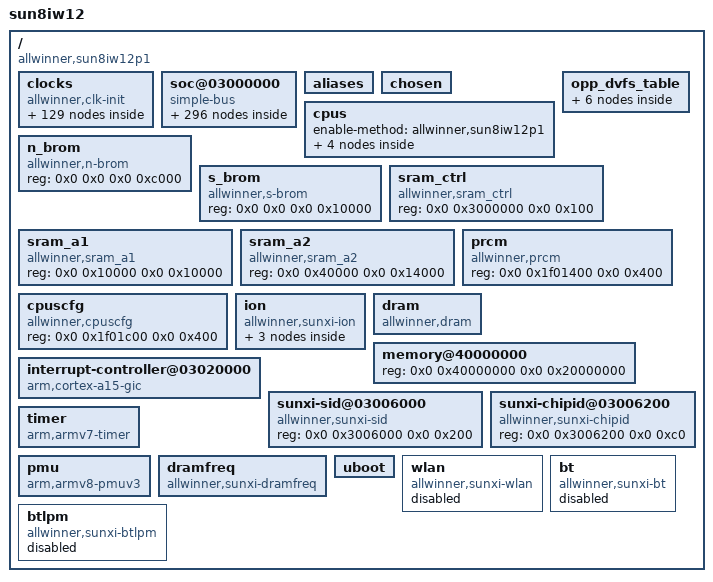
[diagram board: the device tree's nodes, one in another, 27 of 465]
/dts-v1/;

/memreserve/	0x0000000040020000 0x0000000000000800;
/memreserve/	0x0000000048100000 0x0000000000004000;
/memreserve/	0x0000000048104000 0x0000000000001000;
/memreserve/	0x0000000048105000 0x0000000000001000;
/ {
	model = "sun8iw12";
	compatible = "allwinner,sun8iw12p1";
	interrupt-parent = <0x1>;
	#address-cells = <0x2>;
	#size-cells = <0x2>;

	clocks {
		compatible = "allwinner,clk-init";
		device_type = "clocks";
		#address-cells = <0x2>;
		#size-cells = <0x2>;
		ranges;
		reg = <0x0 0x3001000 0x0 0x1000 0x0 0x7010000 0x0 0x400 0x0 0x7000060 0x0 0x4>;

		losc {
			#clock-cells = <0x0>;
			compatible = "allwinner,fixed-clock";
			clock-frequency = <0x8000>;
			clock-output-names = "losc";
			linux,phandle = <0x12>;
			phandle = <0x12>;
		};

		iosc {
			#clock-cells = <0x0>;
			compatible = "allwinner,fixed-clock";
			clock-frequency = <0xf42400>;
			clock-output-names = "iosc";
			linux,phandle = <0x13>;
			phandle = <0x13>;
		};

		hosc {
			#clock-cells = <0x0>;
			compatible = "allwinner,fixed-clock";
			clock-frequency = <0x16e3600>;
			clock-output-names = "hosc";
			linux,phandle = <0x6>;
			phandle = <0x6>;
		};

		osc48m {
			#clock-cells = <0x0>;
			compatible = "allwinner,fixed-clock";
			clock-frequency = <0x2dc6c00>;
			clock-output-names = "osc48m";
			linux,phandle = <0x7>;
			phandle = <0x7>;
		};

		pll_cpu {
			#clock-cells = <0x0>;
			compatible = "allwinner,pll-clock";
			lock-mode = "new";
			clock-output-names = "pll_cpu";
			linux,phandle = <0xc4>;
			phandle = <0xc4>;
		};

		pll_ddr0 {
			#clock-cells = <0x0>;
			compatible = "allwinner,pll-clock";
			lock-mode = "new";
			clock-output-names = "pll_ddr0";
			linux,phandle = <0xc6>;
			phandle = <0xc6>;
		};

		pll_ddr1 {
			#clock-cells = <0x0>;
			compatible = "allwinner,pll-clock";
			lock-mode = "new";
			clock-output-names = "pll_ddr1";
			linux,phandle = <0xc7>;
			phandle = <0xc7>;
		};

		pll_periph0 {
			#clock-cells = <0x0>;
			compatible = "allwinner,pll-clock";
			assigned-clock-rates = <0x23c34600>;
			lock-mode = "new";
			clock-output-names = "pll_periph0";
			linux,phandle = <0x2>;
			phandle = <0x2>;
		};

		pll_periph1 {
			#clock-cells = <0x0>;
			compatible = "allwinner,pll-clock";
			assigned-clock-rates = <0x23c34600>;
			lock-mode = "new";
			clock-output-names = "pll_periph1";
			linux,phandle = <0x3>;
			phandle = <0x3>;
		};

		pll_video0 {
			#clock-cells = <0x0>;
			compatible = "allwinner,pll-clock";
			lock-mode = "new";
			clock-output-names = "pll_video0";
			linux,phandle = <0x5>;
			phandle = <0x5>;
		};

		pll_ve {
			#clock-cells = <0x0>;
			compatible = "allwinner,pll-clock";
			device_type = "clk_pll_ve";
			lock-mode = "new";
			clock-output-names = "pll_ve";
			linux,phandle = <0x23>;
			phandle = <0x23>;
		};

		pll_de {
			#clock-cells = <0x0>;
			compatible = "allwinner,pll-clock";
			lock-mode = "new";
			clock-output-names = "pll_de";
			linux,phandle = <0x9>;
			phandle = <0x9>;
		};

		pll_isp {
			#clock-cells = <0x0>;
			compatible = "allwinner,pll-clock";
			lock-mode = "new";
			clock-output-names = "pll_isp";
			linux,phandle = <0x95>;
			phandle = <0x95>;
		};

		pll_audio {
			#clock-cells = <0x0>;
			compatible = "allwinner,pll-clock";
			lock-mode = "new";
			clock-output-names = "pll_audio";
			linux,phandle = <0x4>;
			phandle = <0x4>;
		};

		pll_eve {
			#clock-cells = <0x0>;
			compatible = "allwinner,pll-clock";
			device_type = "clk_pll_eve";
			lock-mode = "new";
			clock-output-names = "pll_eve";
			linux,phandle = <0x1d>;
			phandle = <0x1d>;
		};

		pll_cve {
			#clock-cells = <0x0>;
			compatible = "allwinner,pll-clock";
			lock-mode = "new";
			clock-output-names = "pll_cve";
			linux,phandle = <0x1f>;
			phandle = <0x1f>;
		};

		pll_ise {
			#clock-cells = <0x0>;
			compatible = "allwinner,pll-clock";
			lock-mode = "new";
			clock-output-names = "pll_ise";
			linux,phandle = <0x21>;
			phandle = <0x21>;
		};

		pll_periph0x2 {
			#clock-cells = <0x0>;
			compatible = "allwinner,fixed-factor-clock";
			clocks = <0x2>;
			clock-mult = <0x2>;
			clock-div = <0x1>;
			clock-output-names = "pll_periph0x2";
			linux,phandle = <0x70>;
			phandle = <0x70>;
		};

		periph32k {
			#clock-cells = <0x0>;
			compatible = "allwinner,fixed-factor-clock";
			clocks = <0x2>;
			clock-mult = <0x2>;
			clock-div = <0x8f0d>;
			clock-output-names = "periph32k";
			linux,phandle = <0xb>;
			phandle = <0xb>;
		};

		pll_periph1x2 {
			#clock-cells = <0x0>;
			compatible = "allwinner,fixed-factor-clock";
			clocks = <0x3>;
			clock-mult = <0x2>;
			clock-div = <0x1>;
			clock-output-names = "pll_periph1x2";
			linux,phandle = <0xb0>;
			phandle = <0xb0>;
		};

		pll_periph0d24 {
			#clock-cells = <0x0>;
			compatible = "allwinner,fixed-factor-clock";
			clocks = <0x2>;
			clock-mult = <0x1>;
			clock-div = <0x18>;
			clock-output-names = "pll_periph0d24";
		};

		pll_audiox4 {
			#clock-cells = <0x0>;
			compatible = "allwinner,fixed-factor-clock";
			clocks = <0x4>;
			clock-mult = <0x4>;
			clock-div = <0x1>;
			clock-output-names = "pll_audiox4";
		};

		pll_audiox2 {
			#clock-cells = <0x0>;
			compatible = "allwinner,fixed-factor-clock";
			clocks = <0x4>;
			clock-mult = <0x2>;
			clock-div = <0x1>;
			clock-output-names = "pll_audiox2";
		};

		pll_video0x4 {
			#clock-cells = <0x0>;
			compatible = "allwinner,fixed-factor-clock";
			clocks = <0x5>;
			clock-mult = <0x4>;
			clock-div = <0x1>;
			clock-output-names = "pll_video0x4";
		};

		hoscd2 {
			#clock-cells = <0x0>;
			compatible = "allwinner,fixed-factor-clock";
			clocks = <0x6>;
			clock-mult = <0x1>;
			clock-div = <0x2>;
			clock-output-names = "hoscd2";
		};

		osc48md4 {
			#clock-cells = <0x0>;
			compatible = "allwinner,fixed-factor-clock";
			clocks = <0x7>;
			clock-mult = <0x1>;
			clock-div = <0x4>;
			clock-output-names = "osc48md4";
			linux,phandle = <0x45>;
			phandle = <0x45>;
		};

		cpu {
			#clock-cells = <0x0>;
			compatible = "allwinner,periph-clock";
			clock-output-names = "cpu";
		};

		axi {
			#clock-cells = <0x0>;
			compatible = "allwinner,periph-clock";
			clock-output-names = "axi";
		};

		cpuapb {
			#clock-cells = <0x0>;
			compatible = "allwinner,periph-clock";
			clock-output-names = "cpuapb";
		};

		psi {
			#clock-cells = <0x0>;
			compatible = "allwinner,periph-clock";
			clock-output-names = "psi";
		};

		ahb1 {
			#clock-cells = <0x0>;
			compatible = "allwinner,periph-clock";
			clock-output-names = "ahb1";
		};

		ahb2 {
			#clock-cells = <0x0>;
			compatible = "allwinner,periph-clock";
			clock-output-names = "ahb2";
		};

		ahb3 {
			#clock-cells = <0x0>;
			compatible = "allwinner,periph-clock";
			clock-output-names = "ahb3";
		};

		apb1 {
			#clock-cells = <0x0>;
			compatible = "allwinner,periph-clock";
			clock-output-names = "apb1";
		};

		apb2 {
			#clock-cells = <0x0>;
			compatible = "allwinner,periph-clock";
			clock-output-names = "apb2";
		};

		mbus {
			#clock-cells = <0x0>;
			compatible = "allwinner,periph-clock";
			clock-output-names = "mbus";
		};

		de {
			#clock-cells = <0x0>;
			compatible = "allwinner,periph-clock";
			assigned-clocks = <0x8>;
			assigned-clock-parents = <0x9>;
			assigned-clock-rates = <0x19bfcc00>;
			clock-output-names = "de";
			linux,phandle = <0x8>;
			phandle = <0x8>;
		};

		di {
			#clock-cells = <0x0>;
			compatible = "allwinner,periph-clock";
			clock-output-names = "di";
			linux,phandle = <0xaf>;
			phandle = <0xaf>;
		};

		g2d {
			#clock-cells = <0x0>;
			compatible = "allwinner,periph-clock";
			clock-output-names = "g2d";
			linux,phandle = <0x87>;
			phandle = <0x87>;
		};

		ve {
			#clock-cells = <0x0>;
			compatible = "allwinner,periph-clock";
			clock-output-names = "ve";
			linux,phandle = <0x24>;
			phandle = <0x24>;
		};

		eve {
			#clock-cells = <0x0>;
			compatible = "allwinner,periph-clock";
			clock-output-names = "eve";
			linux,phandle = <0x1e>;
			phandle = <0x1e>;
		};

		cve {
			#clock-cells = <0x0>;
			compatible = "allwinner,periph-clock";
			clock-output-names = "cve";
			linux,phandle = <0x20>;
			phandle = <0x20>;
		};

		ce {
			#clock-cells = <0x0>;
			compatible = "allwinner,periph-clock";
			clock-output-names = "ce";
			linux,phandle = <0xae>;
			phandle = <0xae>;
		};

		ise {
			#clock-cells = <0x0>;
			compatible = "allwinner,periph-clock";
			clock-output-names = "ise";
			linux,phandle = <0x22>;
			phandle = <0x22>;
		};

		isp {
			#clock-cells = <0x0>;
			compatible = "allwinner,periph-clock";
			clock-output-names = "isp";
			linux,phandle = <0x9a>;
			phandle = <0x9a>;
		};

		dma {
			#clock-cells = <0x0>;
			compatible = "allwinner,periph-clock";
			clock-output-names = "dma";
			linux,phandle = <0x11>;
			phandle = <0x11>;
		};

		msgbox {
			#clock-cells = <0x0>;
			compatible = "allwinner,periph-clock";
			clock-output-names = "msgbox";
			linux,phandle = <0x14>;
			phandle = <0x14>;
		};

		hwspinlock_rst {
			#clock-cells = <0x0>;
			compatible = "allwinner,periph-clock";
			clock-output-names = "hwspinlock_rst";
			linux,phandle = <0x15>;
			phandle = <0x15>;
		};

		hwspinlock_bus {
			#clock-cells = <0x0>;
			compatible = "allwinner,periph-clock";
			clock-output-names = "hwspinlock_bus";
			linux,phandle = <0x16>;
			phandle = <0x16>;
		};

		hstimer {
			#clock-cells = <0x0>;
			compatible = "allwinner,periph-clock";
			clock-output-names = "hstimer";
		};

		avs {
			#clock-cells = <0x0>;
			compatible = "allwinner,periph-clock";
			clock-output-names = "avs";
		};

		dbgsys {
			#clock-cells = <0x0>;
			compatible = "allwinner,periph-clock";
			clock-output-names = "dbgsys";
		};

		pwm {
			#clock-cells = <0x0>;
			compatible = "allwinner,periph-clock";
			clock-output-names = "pwm";
			linux,phandle = <0x88>;
			phandle = <0x88>;
		};

		sdram {
			#clock-cells = <0x0>;
			compatible = "allwinner,periph-clock";
			clock-output-names = "sdram";
		};

		nand0 {
			#clock-cells = <0x0>;
			compatible = "allwinner,periph-clock";
			clock-output-names = "nand0";
			linux,phandle = <0xb1>;
			phandle = <0xb1>;
		};

		nand1 {
			#clock-cells = <0x0>;
			compatible = "allwinner,periph-clock";
			clock-output-names = "nand1";
			linux,phandle = <0xb2>;
			phandle = <0xb2>;
		};

		sdmmc0_mod {
			#clock-cells = <0x0>;
			compatible = "allwinner,periph-clock";
			clock-output-names = "sdmmc0_mod";
			linux,phandle = <0x76>;
			phandle = <0x76>;
		};

		sdmmc0_bus {
			#clock-cells = <0x0>;
			compatible = "allwinner,periph-clock";
			clock-output-names = "sdmmc0_bus";
			linux,phandle = <0x77>;
			phandle = <0x77>;
		};

		sdmmc0_rst {
			#clock-cells = <0x0>;
			compatible = "allwinner,periph-clock";
			clock-output-names = "sdmmc0_rst";
			linux,phandle = <0x78>;
			phandle = <0x78>;
		};

		sdmmc1_mod {
			#clock-cells = <0x0>;
			compatible = "allwinner,periph-clock";
			clock-output-names = "sdmmc1_mod";
			linux,phandle = <0x7b>;
			phandle = <0x7b>;
		};

		sdmmc1_bus {
			#clock-cells = <0x0>;
			compatible = "allwinner,periph-clock";
			clock-output-names = "sdmmc1_bus";
			linux,phandle = <0x7c>;
			phandle = <0x7c>;
		};

		sdmmc1_rst {
			#clock-cells = <0x0>;
			compatible = "allwinner,periph-clock";
			clock-output-names = "sdmmc1_rst";
			linux,phandle = <0x7d>;
			phandle = <0x7d>;
		};

		sdmmc2_mod {
			#clock-cells = <0x0>;
			compatible = "allwinner,periph-clock";
			clock-output-names = "sdmmc2_mod";
			linux,phandle = <0x71>;
			phandle = <0x71>;
		};

		sdmmc2_bus {
			#clock-cells = <0x0>;
			compatible = "allwinner,periph-clock";
			clock-output-names = "sdmmc2_bus";
			linux,phandle = <0x72>;
			phandle = <0x72>;
		};

		sdmmc2_rst {
			#clock-cells = <0x0>;
			compatible = "allwinner,periph-clock";
			clock-output-names = "sdmmc2_rst";
			linux,phandle = <0x73>;
			phandle = <0x73>;
		};

		uart0 {
			#clock-cells = <0x0>;
			compatible = "allwinner,periph-clock";
			clock-output-names = "uart0";
			linux,phandle = <0x25>;
			phandle = <0x25>;
		};

		uart1 {
			#clock-cells = <0x0>;
			compatible = "allwinner,periph-clock";
			clock-output-names = "uart1";
			linux,phandle = <0x28>;
			phandle = <0x28>;
		};

		uart2 {
			#clock-cells = <0x0>;
			compatible = "allwinner,periph-clock";
			clock-output-names = "uart2";
			linux,phandle = <0x2b>;
			phandle = <0x2b>;
		};

		uart3 {
			#clock-cells = <0x0>;
			compatible = "allwinner,periph-clock";
			clock-output-names = "uart3";
			linux,phandle = <0x2e>;
			phandle = <0x2e>;
		};

		uart4 {
			#clock-cells = <0x0>;
			compatible = "allwinner,periph-clock";
			clock-output-names = "uart4";
			linux,phandle = <0x31>;
			phandle = <0x31>;
		};

		twi0 {
			#clock-cells = <0x0>;
			compatible = "allwinner,periph-clock";
			clock-output-names = "twi0";
			linux,phandle = <0x34>;
			phandle = <0x34>;
		};

		twi1 {
			#clock-cells = <0x0>;
			compatible = "allwinner,periph-clock";
			clock-output-names = "twi1";
			linux,phandle = <0x37>;
			phandle = <0x37>;
		};

		twi2 {
			#clock-cells = <0x0>;
			compatible = "allwinner,periph-clock";
			clock-output-names = "twi2";
			linux,phandle = <0x3a>;
			phandle = <0x3a>;
		};

		twi3 {
			#clock-cells = <0x0>;
			compatible = "allwinner,periph-clock";
			clock-output-names = "twi3";
			linux,phandle = <0x3d>;
			phandle = <0x3d>;
		};

		spi0 {
			#clock-cells = <0x0>;
			compatible = "allwinner,periph-clock";
			clock-output-names = "spi0";
			linux,phandle = <0x60>;
			phandle = <0x60>;
		};

		spi1 {
			#clock-cells = <0x0>;
			compatible = "allwinner,periph-clock";
			clock-output-names = "spi1";
			linux,phandle = <0x64>;
			phandle = <0x64>;
		};

		spi2 {
			#clock-cells = <0x0>;
			compatible = "allwinner,periph-clock";
			clock-output-names = "spi2";
			linux,phandle = <0x68>;
			phandle = <0x68>;
		};

		spi3 {
			#clock-cells = <0x0>;
			compatible = "allwinner,periph-clock";
			clock-output-names = "spi3";
			linux,phandle = <0x6c>;
			phandle = <0x6c>;
		};

		ephy_25m {
			#clock-cells = <0x0>;
			compatible = "allwinner,periph-clock";
			clock-output-names = "ephy_25m";
			linux,phandle = <0xc1>;
			phandle = <0xc1>;
		};

		gmac {
			#clock-cells = <0x0>;
			compatible = "allwinner,periph-clock";
			clock-output-names = "gmac";
			linux,phandle = <0xc0>;
			phandle = <0xc0>;
		};

		gpadc {
			#clock-cells = <0x0>;
			compatible = "allwinner,periph-clock";
			clock-output-names = "gpadc";
			linux,phandle = <0xbf>;
			phandle = <0xbf>;
		};

		ths {
			#clock-cells = <0x0>;
			compatible = "allwinner,periph-clock";
			clock-output-names = "ths";
			linux,phandle = <0xb6>;
			phandle = <0xb6>;
		};

		i2s0 {
			#clock-cells = <0x0>;
			compatible = "allwinner,periph-clock";
			clock-output-names = "i2s0";
			linux,phandle = <0x50>;
			phandle = <0x50>;
		};

		i2s1 {
			#clock-cells = <0x0>;
			compatible = "allwinner,periph-clock";
			clock-output-names = "i2s1";
			linux,phandle = <0x53>;
			phandle = <0x53>;
		};

		i2s2 {
			#clock-cells = <0x0>;
			compatible = "allwinner,periph-clock";
			clock-output-names = "i2s2";
			linux,phandle = <0x54>;
			phandle = <0x54>;
		};

		dmic {
			#clock-cells = <0x0>;
			compatible = "allwinner,periph-clock";
			clock-output-names = "dmic";
			linux,phandle = <0x57>;
			phandle = <0x57>;
		};

		codec_1x {
			#clock-cells = <0x0>;
			compatible = "allwinner,periph-clock";
			clock-output-names = "codec_1x";
			linux,phandle = <0x4a>;
			phandle = <0x4a>;
		};

		codec_4x {
			#clock-cells = <0x0>;
			compatible = "allwinner,periph-clock";
			clock-output-names = "codec_4x";
		};

		usbphy0 {
			#clock-cells = <0x0>;
			compatible = "allwinner,periph-clock";
			clock-output-names = "usbphy0";
			linux,phandle = <0x40>;
			phandle = <0x40>;
		};

		usbphy1 {
			#clock-cells = <0x0>;
			compatible = "allwinner,periph-clock";
			clock-output-names = "usbphy1";
			linux,phandle = <0x46>;
			phandle = <0x46>;
		};

		usbohci0 {
			#clock-cells = <0x0>;
			compatible = "allwinner,periph-clock";
			clock-output-names = "usbohci0";
			linux,phandle = <0x43>;
			phandle = <0x43>;
		};

		usbohci0_12m {
			#clock-cells = <0x0>;
			compatible = "allwinner,periph-clock";
			clock-output-names = "usbohci0_12m";
			linux,phandle = <0x44>;
			phandle = <0x44>;
		};

		usbohci1 {
			#clock-cells = <0x0>;
			compatible = "allwinner,periph-clock";
			clock-output-names = "usbohci1";
			linux,phandle = <0x48>;
			phandle = <0x48>;
		};

		usbohci1_12m {
			#clock-cells = <0x0>;
			compatible = "allwinner,periph-clock";
			clock-output-names = "usbohci1_12m";
			linux,phandle = <0x49>;
			phandle = <0x49>;
		};

		usbehci0 {
			#clock-cells = <0x0>;
			compatible = "allwinner,periph-clock";
			clock-output-names = "usbehci0";
			linux,phandle = <0x42>;
			phandle = <0x42>;
		};

		usbehci1 {
			#clock-cells = <0x0>;
			compatible = "allwinner,periph-clock";
			clock-output-names = "usbehci1";
			linux,phandle = <0x47>;
			phandle = <0x47>;
		};

		usbotg {
			#clock-cells = <0x0>;
			compatible = "allwinner,periph-clock";
			clock-output-names = "usbotg";
			linux,phandle = <0x41>;
			phandle = <0x41>;
		};

		hdmi {
			#clock-cells = <0x0>;
			compatible = "allwinner,periph-clock";
			clock-output-names = "hdmi";
			linux,phandle = <0x83>;
			phandle = <0x83>;
		};

		hdmi_slow {
			#clock-cells = <0x0>;
			compatible = "allwinner,periph-clock";
			clock-output-names = "hdmi_slow";
			linux,phandle = <0x84>;
			phandle = <0x84>;
		};

		hdmi_cec {
			#clock-cells = <0x0>;
			compatible = "allwinner,periph-clock";
			assigned-clocks = <0xa>;
			assigned-clock-parents = <0xb>;
			clock-output-names = "hdmi_cec";
			linux,phandle = <0xa>;
			phandle = <0xa>;
		};

		mipi_dphy0 {
			#clock-cells = <0x0>;
			compatible = "allwinner,periph-clock";
			clock-output-names = "mipi_dphy0";
			linux,phandle = <0x82>;
			phandle = <0x82>;
		};

		mipi_host0 {
			#clock-cells = <0x0>;
			compatible = "allwinner,periph-clock";
			assigned-clocks = <0xc>;
			assigned-clock-parents = <0x6>;
			clock-output-names = "mipi_host0";
			linux,phandle = <0xc>;
			phandle = <0xc>;
		};

		display_top {
			#clock-cells = <0x0>;
			compatible = "allwinner,periph-clock";
			clock-output-names = "display_top";
			linux,phandle = <0x80>;
			phandle = <0x80>;
		};

		tcon_lcd {
			#clock-cells = <0x0>;
			compatible = "allwinner,periph-clock";
			clock-output-names = "tcon_lcd";
			linux,phandle = <0xe>;
			phandle = <0xe>;
		};

		tcon_tv {
			#clock-cells = <0x0>;
			compatible = "allwinner,periph-clock";
			clock-output-names = "tcon_tv";
			linux,phandle = <0x81>;
			phandle = <0x81>;
		};

		lvds {
			#clock-cells = <0x0>;
			compatible = "allwinner,periph-clock";
			assigned-clocks = <0xd>;
			assigned-clock-parents = <0xe>;
			clock-output-names = "lvds";
			linux,phandle = <0xd>;
			phandle = <0xd>;
		};

		tve {
			#clock-cells = <0x0>;
			compatible = "allwinner,periph-clock";
			clock-output-names = "tve";
			linux,phandle = <0x86>;
			phandle = <0x86>;
		};

		tve_top {
			#clock-cells = <0x0>;
			compatible = "allwinner,periph-clock";
			clock-output-names = "tve_top";
			linux,phandle = <0x85>;
			phandle = <0x85>;
		};

		csi_misc0 {
			#clock-cells = <0x0>;
			compatible = "allwinner,periph-clock";
			clock-output-names = "csi_misc0";
			linux,phandle = <0xa3>;
			phandle = <0xa3>;
		};

		csi_misc1 {
			#clock-cells = <0x0>;
			compatible = "allwinner,periph-clock";
			clock-output-names = "csi_misc1";
			linux,phandle = <0xa4>;
			phandle = <0xa4>;
		};

		csi_misc2 {
			#clock-cells = <0x0>;
			compatible = "allwinner,periph-clock";
			clock-output-names = "csi_misc2";
			linux,phandle = <0xa5>;
			phandle = <0xa5>;
		};

		csi_misc3 {
			#clock-cells = <0x0>;
			compatible = "allwinner,periph-clock";
			clock-output-names = "csi_misc3";
			linux,phandle = <0xa6>;
			phandle = <0xa6>;
		};

		csi_top {
			#clock-cells = <0x0>;
			compatible = "allwinner,periph-clock";
			clock-output-names = "csi_top";
			linux,phandle = <0x94>;
			phandle = <0x94>;
		};

		csi_master0 {
			#clock-cells = <0x0>;
			compatible = "allwinner,periph-clock";
			clock-output-names = "csi_master0";
			linux,phandle = <0x96>;
			phandle = <0x96>;
		};

		csi_master1 {
			#clock-cells = <0x0>;
			compatible = "allwinner,periph-clock";
			clock-output-names = "csi_master1";
			linux,phandle = <0x97>;
			phandle = <0x97>;
		};

		csi_master2 {
			#clock-cells = <0x0>;
			compatible = "allwinner,periph-clock";
			clock-output-names = "csi_master2";
			linux,phandle = <0x98>;
			phandle = <0x98>;
		};

		csi_master3 {
			#clock-cells = <0x0>;
			compatible = "allwinner,periph-clock";
			clock-output-names = "csi_master3";
			linux,phandle = <0x99>;
			phandle = <0x99>;
		};

		vdpo {
			#clock-cells = <0x0>;
			compatible = "allwinner,periph-clock";
			clock-output-names = "vdpo";
		};

		pio {
			#clock-cells = <0x0>;
			compatible = "allwinner,periph-clock";
			clock-output-names = "pio";
			linux,phandle = <0x10>;
			phandle = <0x10>;
		};

		cpurcir {
			#clock-cells = <0x0>;
			compatible = "allwinner,periph-cpus-clock";
			clock-output-names = "cpurcir";
			linux,phandle = <0x18>;
			phandle = <0x18>;
		};

		losc_out {
			#clock-cells = <0x0>;
			compatible = "allwinner,periph-cpus-clock";
			clock-output-names = "losc_out";
			linux,phandle = <0xc8>;
			phandle = <0xc8>;
		};

		cpurcpus_pll {
			#clock-cells = <0x0>;
			compatible = "allwinner,periph-cpus-clock";
			clock-output-names = "cpurcpus_pll";
		};

		cpurcpus {
			#clock-cells = <0x0>;
			compatible = "allwinner,periph-cpus-clock";
			clock-output-names = "cpurcpus";
		};

		cpurahbs {
			#clock-cells = <0x0>;
			compatible = "allwinner,periph-cpus-clock";
			clock-output-names = "cpurahbs";
		};

		cpurapbs1 {
			#clock-cells = <0x0>;
			compatible = "allwinner,periph-cpus-clock";
			clock-output-names = "cpurapbs1";
		};

		cpurapbs2_pll {
			#clock-cells = <0x0>;
			compatible = "allwinner,periph-cpus-clock";
			clock-output-names = "cpurapbs2_pll";
		};

		cpurapbs2 {
			#clock-cells = <0x0>;
			compatible = "allwinner,periph-cpus-clock";
			clock-output-names = "cpurapbs2";
		};

		cpurpio {
			#clock-cells = <0x0>;
			compatible = "allwinner,periph-cpus-clock";
			clock-output-names = "cpurpio";
			linux,phandle = <0xf>;
			phandle = <0xf>;
		};

		spwm {
			#clock-cells = <0x0>;
			compatible = "allwinner,periph-cpus-clock";
			clock-output-names = "spwm";
			linux,phandle = <0x92>;
			phandle = <0x92>;
		};
	};

	soc@03000000 {
		compatible = "simple-bus";
		#address-cells = <0x2>;
		#size-cells = <0x2>;
		ranges;
		device_type = "soc";

		pinctrl@07022000 {
			compatible = "allwinner,sun8iw12p1-r-pinctrl";
			reg = <0x0 0x7022000 0x0 0x400>;
			interrupts = <0x0 0x6e 0x4>;
			clocks = <0xf>;
			device_type = "r_pio";
			gpio-controller;
			interrupt-controller;
			#interrupt-cells = <0x2>;
			#size-cells = <0x0>;
			#gpio-cells = <0x6>;
			linux,phandle = <0xc9>;
			phandle = <0xc9>;

			s_rsb0@0 {
				allwinner,pins = "PL0", "PL1";
				allwinner,function = "s_rsb0";
				allwinner,muxsel = <0x2>;
				allwinner,drive = <0x2>;
				allwinner,pull = <0x1>;
				linux,phandle = <0x1a>;
				phandle = <0x1a>;
			};

			s_twi0@0 {
				allwinner,pins = "PL0", "PL1";
				allwinner,function = "s_twi0";
				allwinner,muxsel = <0x3>;
				allwinner,drive = <0x2>;
				allwinner,pull = <0x1>;
				linux,phandle = <0x1b>;
				phandle = <0x1b>;
			};

			s_cir0@0 {
				allwinner,pins = "PL13";
				allwinner,function = "s_cir0";
				allwinner,muxsel = <0x2>;
				allwinner,drive = <0x2>;
				allwinner,pull = <0x1>;
				linux,phandle = <0x17>;
				phandle = <0x17>;
			};

			spwm0@0 {
				linux,phandle = <0xee>;
				phandle = <0xee>;
				allwinner,pins = "PL10";
				allwinner,function = "spwm0";
				allwinner,pname = "pwm_positive";
				allwinner,muxsel = <0x2>;
				allwinner,pull = <0x0>;
				allwinner,drive = <0xffffffff>;
				allwinner,data = <0xffffffff>;
			};

			spwm0@1 {
				linux,phandle = <0xef>;
				phandle = <0xef>;
				allwinner,pins = "PL10";
				allwinner,function = "spwm0";
				allwinner,pname = "pwm_positive";
				allwinner,muxsel = <0x7>;
				allwinner,pull = <0x0>;
				allwinner,drive = <0xffffffff>;
				allwinner,data = <0xffffffff>;
			};

			s_uart0@0 {
				linux,phandle = <0xf9>;
				phandle = <0xf9>;
				allwinner,pins = "PL2", "PL3";
				allwinner,function = "s_uart0";
				allwinner,pname = "s_uart_tx", "s_uart_rx";
				allwinner,muxsel = <0x2>;
				allwinner,pull = <0xffffffff>;
				allwinner,drive = <0xffffffff>;
				allwinner,data = <0xffffffff>;
			};

			s_rsb0@1 {
				linux,phandle = <0xfa>;
				phandle = <0xfa>;
				allwinner,pins = "PL0", "PL1";
				allwinner,function = "s_rsb0";
				allwinner,pname = "s_rsb_sck", "s_rsb_sda";
				allwinner,muxsel = <0x2>;
				allwinner,pull = <0x1>;
				allwinner,drive = <0x2>;
				allwinner,data = <0xffffffff>;
			};

			s_jtag0@0 {
				linux,phandle = <0xfb>;
				phandle = <0xfb>;
				allwinner,pins = "PL4", "PL5", "PL6", "PL7";
				allwinner,function = "s_jtag0";
				allwinner,pname = "s_jtag_tms", "s_jtag_tck", "s_jtag_tdo", "s_jtag_tdi";
				allwinner,muxsel = <0x2>;
				allwinner,pull = <0x1>;
				allwinner,drive = <0x2>;
				allwinner,data = <0xffffffff>;
			};
		};

		pinctrl@0300b000 {
			compatible = "allwinner,sun8iw12p1-pinctrl";
			reg = <0x0 0x300b000 0x0 0x400>;
			interrupts = <0x0 0x45 0x4 0x0 0x46 0x4 0x0 0x47 0x4 0x0 0x48 0x4 0x0 0x49 0x4>;
			device_type = "pio";
			clocks = <0x10>;
			gpio-controller;
			interrupt-controller;
			#interrupt-cells = <0x2>;
			#size-cells = <0x0>;
			#gpio-cells = <0x6>;
			linux,phandle = <0x4f>;
			phandle = <0x4f>;

			uart0@1 {
				allwinner,pins = "PB9", "PB10";
				allwinner,function = "io_disabled";
				allwinner,muxsel = <0x7>;
				allwinner,drive = <0x1>;
				allwinner,pull = <0x0>;
				linux,phandle = <0x27>;
				phandle = <0x27>;
			};

			uart3@0 {
				allwinner,pins = "PG10", "PG11", "PG12", "PG13";
				allwinner,pname = "uart3_tx", "uart3_rx", "uart3_rts", "uart3_cts";
				allwinner,function = "uart3";
				allwinner,muxsel = <0x4>;
				allwinner,drive = <0x1>;
				allwinner,pull = <0x1>;
				linux,phandle = <0x2f>;
				phandle = <0x2f>;
			};

			uart3@1 {
				allwinner,pins = "PG10", "PG11", "PG12", "PG13";
				allwinner,function = "io_disabled";
				allwinner,muxsel = <0x7>;
				allwinner,drive = <0x1>;
				allwinner,pull = <0x0>;
				linux,phandle = <0x30>;
				phandle = <0x30>;
			};

			twi0@1 {
				allwinner,pins = "PH0", "PH1";
				allwinner,function = "io_disabled";
				allwinner,muxsel = <0x7>;
				allwinner,drive = <0x1>;
				allwinner,pull = <0x0>;
				linux,phandle = <0x36>;
				phandle = <0x36>;
			};

			twi1@1 {
				allwinner,pins = "PH2", "PH3";
				allwinner,function = "io_disabled";
				allwinner,muxsel = <0x7>;
				allwinner,drive = <0x1>;
				allwinner,pull = <0x0>;
				linux,phandle = <0x39>;
				phandle = <0x39>;
			};

			twi2@1 {
				allwinner,pins = "PE16", "PE17";
				allwinner,function = "io_disabled";
				allwinner,muxsel = <0x7>;
				allwinner,drive = <0x1>;
				allwinner,pull = <0x0>;
				linux,phandle = <0x3c>;
				phandle = <0x3c>;
			};

			twi3@1 {
				allwinner,pins = "PI8", "PI9";
				allwinner,function = "io_disabled";
				allwinner,muxsel = <0x7>;
				allwinner,drive = <0x1>;
				allwinner,pull = <0x0>;
				linux,phandle = <0x3f>;
				phandle = <0x3f>;
			};

			ts0@0 {
				allwinner,pins = "PE0", "PE1", "PE2", "PE3", "PE4", "PE5", "PE6", "PE7", "PE8", "PE9", "PE10", "PE11";
				allwinner,pname = "ts0_clk", "ts0_err", "ts0_sync", "ts0_dvld", "ts0_d0", "ts0_d1", "ts0_d2", "ts0_d3", "ts0_d4", "ts0_d5", "ts0_d6", "ts0_d7";
				allwinner,function = "ts0";
				allwinner,muxsel = <0x3>;
				allwinner,drive = <0x1>;
				allwinner,pull = <0x0>;
			};

			ts0_sleep@0 {
				allwinner,pins = "PE0", "PE1", "PE2", "PE3", "PE4", "PE5", "PE6", "PE7", "PE8", "PE9", "PE10", "PE11";
				allwinner,pname = "ts0_clk", "ts0_err", "ts0_sync", "ts0_dvld", "ts0_d0", "ts0_d1", "ts0_d2", "ts0_d3", "ts0_d4", "ts0_d5", "ts0_d6", "ts0_d7";
				allwinner,function = "io_disabled";
				allwinner,muxsel = <0x7>;
				allwinner,drive = <0x1>;
				allwinner,pull = <0x0>;
			};

			ts1@0 {
				allwinner,pins = "PE7", "PE8", "PE9", "PE10", "PE11";
				allwinner,pname = "ts1_clk", "ts1_err", "ts1_sync", "ts1_dvld", "ts1_d0";
				allwinner,function = "ts1";
				allwinner,muxsel = <0x4>;
				allwinner,drive = <0x1>;
				allwinner,pull = <0x0>;
			};

			ts1_sleep@0 {
				allwinner,pins = "PE7", "PE8", "PE9", "PE10", "PE11";
				allwinner,pname = "ts1_clk", "ts1_err", "ts1_sync", "ts1_dvld", "ts1_d0";
				allwinner,function = "io_disabled";
				allwinner,muxsel = <0x7>;
				allwinner,drive = <0x1>;
				allwinner,pull = <0x0>;
			};

			ts2@0 {
				allwinner,pins = "PD0", "PD1", "PD2", "PD3", "PD4", "PD5", "PD6", "PD7", "PD8", "PD9", "PD10", "PD11";
				allwinner,pname = "ts2_clk", "ts2_err", "ts2_sync", "ts2_dvld", "ts2_d0", "ts2_d1", "ts2_d2", "ts2_d3", "ts2_d4", "ts2_d5", "ts2_d6", "ts2_d7";
				allwinner,function = "ts2";
				allwinner,muxsel = <0x4>;
				allwinner,drive = <0x1>;
				allwinner,pull = <0x0>;
			};

			ts2_sleep@0 {
				allwinner,pins = "PD0", "PD1", "PD2", "PD3", "PD4", "PD5", "PD6", "PD7", "PD8", "PD9", "PD10", "PD11";
				allwinner,pname = "ts2_clk", "ts2_err", "ts2_sync", "ts2_dvld", "ts2_d0", "ts2_d1", "ts2_d2", "ts2_d3", "ts2_d4", "ts2_d5", "ts2_d6", "ts2_d7";
				allwinner,function = "io_disabled";
				allwinner,muxsel = <0x7>;
				allwinner,drive = <0x1>;
				allwinner,pull = <0x0>;
			};

			ts3@0 {
				allwinner,pins = "PD7", "PD8", "PD9", "PD10", "PD11";
				allwinner,pname = "ts3_clk", "ts3_err", "ts3_sync", "ts3_dvld", "ts3_d0";
				allwinner,function = "ts3";
				allwinner,muxsel = <0x5>;
				allwinner,drive = <0x1>;
				allwinner,pull = <0x0>;
			};

			ts3_sleep@0 {
				allwinner,pins = "PD7", "PD8", "PD9", "PD10", "PD11";
				allwinner,pname = "ts3_clk", "ts3_err", "ts3_sync", "ts3_dvld", "ts3_d0";
				allwinner,function = "io_disabled";
				allwinner,muxsel = <0x7>;
				allwinner,drive = <0x1>;
				allwinner,pull = <0x0>;
			};

			spi0@2 {
				allwinner,pins = "PC0", "PC2", "PC3", "PC6", "PC7", "PC15", "PC16";
				allwinner,function = "io_disabled";
				allwinner,muxsel = <0x7>;
				allwinner,drive = <0x1>;
				allwinner,pull = <0x0>;
				linux,phandle = <0x63>;
				phandle = <0x63>;
			};

			spi1@2 {
				allwinner,pins = "PH15", "PH14", "PH6", "PH7", "PH8";
				allwinner,function = "io_disabled";
				allwinner,muxsel = <0x7>;
				allwinner,drive = <0x1>;
				allwinner,pull = <0x0>;
				linux,phandle = <0x67>;
				phandle = <0x67>;
			};

			spi2@2 {
				allwinner,pins = "PI1", "PI2", "PI3", "PI4";
				allwinner,function = "io_disabled";
				allwinner,muxsel = <0x7>;
				allwinner,drive = <0x1>;
				allwinner,pull = <0x0>;
				linux,phandle = <0x6b>;
				phandle = <0x6b>;
			};

			spi3@2 {
				allwinner,pins = "PI8", "PI9", "PI10", "PI11";
				allwinner,function = "io_disabled";
				allwinner,muxsel = <0x7>;
				allwinner,drive = <0x1>;
				allwinner,pull = <0x0>;
				linux,phandle = <0x6f>;
				phandle = <0x6f>;
			};

			sdc0@1 {
				allwinner,pins = "PF0", "PF1", "PF2", "PF3", "PF4", "PF5";
				allwinner,function = "io_disabled";
				allwinner,muxsel = <0x7>;
				allwinner,drive = <0x1>;
				allwinner,pull = <0x1>;
				linux,phandle = <0x7a>;
				phandle = <0x7a>;
			};

			sdc1@1 {
				allwinner,pins = "PG0", "PG1", "PG2", "PG3", "PG4", "PG5";
				allwinner,function = "io_disabled";
				allwinner,muxsel = <0x7>;
				allwinner,drive = <0x1>;
				allwinner,pull = <0x1>;
				linux,phandle = <0x7f>;
				phandle = <0x7f>;
			};

			sdc2@1 {
				allwinner,pins = "PC1", "PC4", "PC5", "PC6", "PC7", "PC8", "PC9", "PC10", "PC11", "PC12", "PC13", "PC14";
				allwinner,function = "io_disabled";
				allwinner,muxsel = <0x7>;
				allwinner,drive = <0x1>;
				allwinner,pull = <0x1>;
				linux,phandle = <0x75>;
				phandle = <0x75>;
			};

			aif2@0 {
				allwinner,pins = "PB6", "PB4", "PB5", "PB7";
				allwinner,function = "aif2";
				allwinner,muxsel = <0x2>;
				allwinner,drive = <0x1>;
				allwinner,pull = <0x0>;
				linux,phandle = <0x4b>;
				phandle = <0x4b>;
			};

			aif3@0 {
				allwinner,pins = "PG10", "PG11", "PG12", "PG13";
				allwinner,function = "aif3";
				allwinner,muxsel = <0x2>;
				allwinner,drive = <0x1>;
				allwinner,pull = <0x0>;
				linux,phandle = <0x4c>;
				phandle = <0x4c>;
			};

			aif2_sleep@0 {
				allwinner,pins = "PB6", "PB4", "PB5", "PB7";
				allwinner,function = "io_disabled";
				allwinner,muxsel = <0x7>;
				allwinner,drive = <0x1>;
				allwinner,pull = <0x0>;
				linux,phandle = <0x4d>;
				phandle = <0x4d>;
			};

			aif3_sleep@0 {
				allwinner,pins = "PG10", "PG11", "PG12", "PG13";
				allwinner,function = "io_disabled";
				allwinner,muxsel = <0x7>;
				allwinner,drive = <0x1>;
				allwinner,pull = <0x0>;
				linux,phandle = <0x4e>;
				phandle = <0x4e>;
			};

			daudio0@0 {
				allwinner,pins = "PB4", "PB5", "PB6", "PB7", "PB8";
				allwinner,pname = "i2s0_lrclk", "i2s0_bclk", "i2s0_dout0", "i2s0_din", "i2s0_mclk";
				allwinner,function = "pcm0";
				allwinner,muxsel = <0x3>;
				allwinner,drive = <0x1>;
				allwinner,pull = <0x0>;
				linux,phandle = <0x51>;
				phandle = <0x51>;
			};

			daudio0_sleep@0 {
				allwinner,pins = "PB4", "PB5", "PB6", "PB7", "PB8";
				allwinner,function = "io_disabled";
				allwinner,muxsel = <0x7>;
				allwinner,drive = <0x1>;
				allwinner,pull = <0x0>;
				linux,phandle = <0x52>;
				phandle = <0x52>;
			};

			daudio2@0 {
				allwinner,pins = "PG10", "PG11", "PG12", "PG13";
				allwinner,pname = "i2s2_bclk", "i2s2_lrclk", "i2s2_dout0", "i2s2_din";
				allwinner,function = "pcm2";
				allwinner,muxsel = <0x3>;
				allwinner,drive = <0x1>;
				allwinner,pull = <0x0>;
				linux,phandle = <0x55>;
				phandle = <0x55>;
			};

			daudio2_sleep@0 {
				allwinner,pins = "PG10", "PG11", "PG12", "PG13";
				allwinner,function = "io_disabled";
				allwinner,muxsel = <0x7>;
				allwinner,drive = <0x1>;
				allwinner,pull = <0x0>;
				linux,phandle = <0x56>;
				phandle = <0x56>;
			};

			dmic@0 {
				allwinner,pins = "PG9", "PG10", "PG11", "PG12", "PG13";
				allwinner,function = "dmic0";
				allwinner,muxsel = <0x2>;
				allwinner,drive = <0x1>;
				allwinner,pull = <0x0>;
			};

			dmic_sleep@0 {
				allwinner,pins = "PG9", "PG10", "PG11", "PG12", "PG13";
				allwinner,function = "io_disabled";
				allwinner,muxsel = <0x7>;
				allwinner,drive = <0x1>;
				allwinner,pull = <0x0>;
			};

			dmic@1 {
				allwinner,pins = "PH4", "PH5", "PH6", "PH7", "PH8";
				allwinner,function = "dmic1";
				allwinner,muxsel = <0x4>;
				allwinner,drive = <0x1>;
				allwinner,pull = <0x0>;
				linux,phandle = <0x58>;
				phandle = <0x58>;
			};

			dmic_sleep@1 {
				allwinner,pins = "PH4", "PH5", "PH6", "PH7", "PH8";
				allwinner,function = "io_disabled";
				allwinner,muxsel = <0x7>;
				allwinner,drive = <0x1>;
				allwinner,pull = <0x0>;
				linux,phandle = <0x59>;
				phandle = <0x59>;
			};

			csi_cci0@0 {
				allwinner,pins = "PE16", "PE17";
				allwinner,pname = "csi_cci0_sck", "csi_cci0_sda";
				allwinner,function = "csi_cci0";
				allwinner,muxsel = <0x2>;
				allwinner,drive = <0x1>;
				allwinner,pull = <0x0>;
				allwinner,data = <0x0>;
			};

			csi_cci0@1 {
				allwinner,pins = "PE16", "PE17";
				allwinner,pname = "csi_cci0_sck", "csi_cci0_sda";
				allwinner,function = "io_disabled";
				allwinner,muxsel = <0x7>;
				allwinner,drive = <0x1>;
				allwinner,pull = <0x0>;
				allwinner,data = <0x0>;
			};

			csi_cci1@0 {
				allwinner,pins = "PJ16", "PJ17";
				allwinner,pname = "csi_cci1_sck", "csi_cci1_sda";
				allwinner,function = "csi_cci1";
				allwinner,muxsel = <0x2>;
				allwinner,drive = <0x1>;
				allwinner,pull = <0x0>;
				allwinner,data = <0x0>;
			};

			csi_cci1@1 {
				allwinner,pins = "PJ16", "PJ17";
				allwinner,pname = "csi_cci1_sck", "csi_cci1_sda";
				allwinner,function = "io_disabled";
				allwinner,muxsel = <0x7>;
				allwinner,drive = <0x1>;
				allwinner,pull = <0x0>;
				allwinner,data = <0x0>;
			};

			csi_cci2@0 {
				allwinner,pins = "PI1", "PI2";
				allwinner,pname = "csi_cci2_sck", "csi_cci2_sda";
				allwinner,function = "csi_cci2";
				allwinner,muxsel = <0x3>;
				allwinner,drive = <0x1>;
				allwinner,pull = <0x0>;
				allwinner,data = <0x0>;
			};

			csi_cci2@1 {
				allwinner,pins = "PI1", "PI2";
				allwinner,pname = "csi_cci2_sck", "csi_cci2_sda";
				allwinner,function = "io_disabled";
				allwinner,muxsel = <0x7>;
				allwinner,drive = <0x1>;
				allwinner,pull = <0x0>;
				allwinner,data = <0x0>;
			};

			csi_cci3@0 {
				allwinner,pins = "PI8", "PI9";
				allwinner,pname = "csi_cci3_sck", "csi_cci3_sda";
				allwinner,function = "csi_cci3";
				allwinner,muxsel = <0x3>;
				allwinner,drive = <0x1>;
				allwinner,pull = <0x0>;
				allwinner,data = <0x0>;
			};

			csi_cci3@1 {
				allwinner,pins = "PI8", "PI9";
				allwinner,pname = "csi_cci3_sck", "csi_cci3_sda";
				allwinner,function = "io_disabled";
				allwinner,muxsel = <0x7>;
				allwinner,drive = <0x1>;
				allwinner,pull = <0x0>;
				allwinner,data = <0x0>;
			};

			csi_mclk0@0 {
				allwinner,pins = "PE1";
				allwinner,pname = "csi_mclk0";
				allwinner,function = "csi_mclk0";
				allwinner,muxsel = <0x2>;
				allwinner,drive = <0x1>;
				allwinner,pull = <0x0>;
				allwinner,data = <0x0>;
				linux,phandle = <0x9b>;
				phandle = <0x9b>;
			};

			csi_mclk0@1 {
				allwinner,pins = "PE1";
				allwinner,pname = "csi_mclk0";
				allwinner,function = "io_disabled";
				allwinner,muxsel = <0x7>;
				allwinner,drive = <0x1>;
				allwinner,pull = <0x0>;
				allwinner,data = <0x0>;
				linux,phandle = <0x9c>;
				phandle = <0x9c>;
			};

			csi_mclk1@0 {
				allwinner,pins = "PJ1";
				allwinner,pname = "csi_mclk1";
				allwinner,function = "csi_mclk1";
				allwinner,muxsel = <0x2>;
				allwinner,drive = <0x1>;
				allwinner,pull = <0x0>;
				allwinner,data = <0x0>;
				linux,phandle = <0x9d>;
				phandle = <0x9d>;
			};

			csi_mclk1@1 {
				allwinner,pins = "PJ1";
				allwinner,pname = "csi_mclk1";
				allwinner,function = "io_disabled";
				allwinner,muxsel = <0x7>;
				allwinner,drive = <0x1>;
				allwinner,pull = <0x0>;
				allwinner,data = <0x0>;
				linux,phandle = <0x9e>;
				phandle = <0x9e>;
			};

			csi_mclk2@0 {
				allwinner,pins = "PI0";
				allwinner,pname = "csi_mclk2";
				allwinner,function = "csi_mclk2";
				allwinner,muxsel = <0x3>;
				allwinner,drive = <0x1>;
				allwinner,pull = <0x0>;
				allwinner,data = <0x0>;
				linux,phandle = <0x9f>;
				phandle = <0x9f>;
			};

			csi_mclk2@1 {
				allwinner,pins = "PI0";
				allwinner,pname = "csi_mclk2";
				allwinner,function = "io_disabled";
				allwinner,muxsel = <0x7>;
				allwinner,drive = <0x1>;
				allwinner,pull = <0x0>;
				allwinner,data = <0x0>;
				linux,phandle = <0xa0>;
				phandle = <0xa0>;
			};

			csi_mclk3@0 {
				allwinner,pins = "PI7";
				allwinner,pname = "csi_mclk3";
				allwinner,function = "csi_mclk3";
				allwinner,muxsel = <0x3>;
				allwinner,drive = <0x1>;
				allwinner,pull = <0x0>;
				allwinner,data = <0x0>;
				linux,phandle = <0xa1>;
				phandle = <0xa1>;
			};

			csi_mclk3@1 {
				allwinner,pins = "PI7";
				allwinner,pname = "csi_mclk3";
				allwinner,function = "io_disabled";
				allwinner,muxsel = <0x7>;
				allwinner,drive = <0x1>;
				allwinner,pull = <0x0>;
				allwinner,data = <0x0>;
				linux,phandle = <0xa2>;
				phandle = <0xa2>;
			};

			csi2@1 {
				allwinner,pins = "PE0", "PE2", "PE3", "PE4", "PE5", "PE6", "PE7", "PE8", "PE9", "PE10", "PE11", "PE12", "PE13", "PE14", "PE15";
				allwinner,pname = "csi2_pck", "csi2_hsync", "csi2_vsync", "csi2_d0", "csi2_d1", "csi2_d2", "csi2_d3", "csi2_d4", "csi2_d5", "csi2_d6", "csi2_d7", "csi2_d8", "csi2_d9", "csi2_d10", "csi2_d11";
				allwinner,function = "io_disabled";
				allwinner,muxsel = <0x7>;
				allwinner,drive = <0x1>;
				allwinner,pull = <0x0>;
				allwinner,data = <0x0>;
				linux,phandle = <0xa8>;
				phandle = <0xa8>;
			};

			csi3@1 {
				allwinner,pins = "PJ0", "PJ2", "PJ3", "PJ4", "PJ5", "PJ6", "PJ7", "PJ8", "PJ9", "PJ10", "PJ11", "PJ12", "PJ13", "PJ14", "PJ15";
				allwinner,pname = "csi3_pck", "csi3_hsync", "csi3_vsync", "csi3_d0", "csi3_d1", "csi3_d2", "csi3_d3", "csi3_d4", "csi3_d5", "csi3_d6", "csi3_d7", "csi3_d8", "csi3_d9", "csi3_d10", "csi3_d11";
				allwinner,function = "io_disabled";
				allwinner,muxsel = <0x7>;
				allwinner,drive = <0x1>;
				allwinner,pull = <0x0>;
				allwinner,data = <0x0>;
				linux,phandle = <0xaa>;
				phandle = <0xaa>;
			};

			scr0@0 {
				allwinner,pins = "PH21", "PH24", "PH25", "PH26", "PH27";
				allwinner,pname = "scr0_rst", "scr0_det", "scr0_vccen", "scr0_sck", "scr0_sda";
				allwinner,function = "sim0";
				allwinner,muxsel = <0x2>;
				allwinner,drive = <0x0>;
				allwinner,pull = <0x1>;
			};

			scr0@1 {
				allwinner,pins = "PH22", "PH23";
				allwinner,pname = "scr0_vppen", "scr0_vppp";
				allwinner,function = "sim0";
				allwinner,muxsel = <0x2>;
				allwinner,drive = <0x0>;
				allwinner,pull = <0x1>;
			};

			scr0@2 {
				allwinner,pins = "PH21", "PH22", "PH23", "PH24", "PH25", "PH26", "P27";
				allwinner,function = "io_disabled";
				allwinner,muxsel = <0x7>;
				allwinner,drive = <0x0>;
				allwinner,pull = <0x0>;
			};

			scr1@0 {
				allwinner,pins = "PD15", "PD16", "PD12", "PD13", "PD14";
				allwinner,pname = "scr1_rst", "scr1_det", "scr1_vccen", "scr1_sck", "scr1_sda";
				allwinner,function = "sim1";
				allwinner,muxsel = <0x4>;
				allwinner,drive = <0x1>;
				allwinner,pull = <0x1>;
			};

			scr1@1 {
				allwinner,pins = "PE14", "PE15";
				allwinner,pname = "scr1_vppen", "scr1_vppp";
				allwinner,function = "sim1";
				allwinner,muxsel = <0x3>;
				allwinner,drive = <0x1>;
				allwinner,pull = <0x1>;
			};

			scr1@2 {
				allwinner,pins = "PD15", "PD16", "PD12", "PD13", "PD14", "PE14", "PE15";
				allwinner,function = "io_disabled";
				allwinner,muxsel = <0x7>;
				allwinner,drive = <0x1>;
				allwinner,pull = <0x0>;
			};

			nand0@2 {
				allwinner,pins = "PC0", "PC1", "PC2", "PC3", "PC4", "PC5", "PC6", "PC7", "PC8", "PC9", "PC10", "PC11", "PC12", "PC13", "PC14", "PC15", "PC16";
				allwinner,function = "io_disabled";
				allwinner,muxsel = <0x7>;
				allwinner,drive = <0x1>;
				allwinner,pull = <0x0>;
				linux,phandle = <0xb5>;
				phandle = <0xb5>;
			};

			gmac@1 {
				allwinner,pins = "PA0", "PA1", "PA2", "PA3", "PA4", "PA5", "PA6", "PA7", "PA8", "PA9", "PA10", "PA11", "PA12", "PA13", "PA14", "PA15";
				allwinner,function = "io_disabled";
				allwinner,muxsel = <0x7>;
				allwinner,drive = <0x3>;
				allwinner,pull = <0x0>;
				linux,phandle = <0xc3>;
				phandle = <0xc3>;
			};

			card0_boot_para@0 {
				linux,phandle = <0xca>;
				phandle = <0xca>;
				allwinner,pins = "PF0", "PF1", "PF2", "PF3", "PF4", "PF5";
				allwinner,function = "card0_boot_para";
				allwinner,pname = "sdc_d1", "sdc_d0", "sdc_clk", "sdc_cmd", "sdc_d3", "sdc_d2";
				allwinner,muxsel = <0x2>;
				allwinner,pull = <0x1>;
				allwinner,drive = <0x2>;
				allwinner,data = <0xffffffff>;
			};

			card2_boot_para@0 {
				linux,phandle = <0xcb>;
				phandle = <0xcb>;
				allwinner,pins = "PC4", "PC5", "PC6", "PC7", "PC8", "PC9", "PC10", "PC11", "PC12", "PC13", "PC14", "PC1";
				allwinner,function = "card2_boot_para";
				allwinner,pname = "sdc_clk", "sdc_cmd", "sdc_d0", "sdc_d1", "sdc_d2", "sdc_d3", "sdc_d4", "sdc_d5", "sdc_d6", "sdc_d7", "sdc_emmc_rst", "sdc_ds";
				allwinner,muxsel = <0x3>;
				allwinner,pull = <0x1>;
				allwinner,drive = <0x3>;
				allwinner,data = <0xffffffff>;
			};

			twi_para@0 {
				linux,phandle = <0xcc>;
				phandle = <0xcc>;
				allwinner,pins = "PH0", "PH1";
				allwinner,function = "twi_para";
				allwinner,pname = "twi_scl", "twi_sda";
				allwinner,muxsel = <0x2>;
				allwinner,pull = <0xffffffff>;
				allwinner,drive = <0xffffffff>;
				allwinner,data = <0xffffffff>;
			};

			uart_para@0 {
				linux,phandle = <0xcd>;
				phandle = <0xcd>;
				allwinner,pins = "PB9", "PB10";
				allwinner,function = "uart_para";
				allwinner,pname = "uart_debug_tx", "uart_debug_rx";
				allwinner,muxsel = <0x2>;
				allwinner,pull = <0x1>;
				allwinner,drive = <0xffffffff>;
				allwinner,data = <0xffffffff>;
			};

			jtag_para@0 {
				linux,phandle = <0xce>;
				phandle = <0xce>;
				allwinner,pins = "PF0", "PF1", "PF3", "PF5";
				allwinner,function = "jtag_para";
				allwinner,pname = "jtag_ms", "jtag_ck", "jtag_do", "jtag_di";
				allwinner,muxsel = <0x3>;
				allwinner,pull = <0xffffffff>;
				allwinner,drive = <0xffffffff>;
				allwinner,data = <0xffffffff>;
			};

			gmac0@0 {
				linux,phandle = <0xcf>;
				phandle = <0xcf>;
				allwinner,pins = "PA0", "PA1", "PA2", "PA3", "PA4", "PA5", "PA6", "PA7", "PA8", "PA9", "PA10", "PA11", "PA12", "PA13", "PA14", "PA15";
				allwinner,function = "gmac0";
				allwinner,pname = "gmac_rxd3", "gmac_rxd2", "gmac_rxd1", "gmac_rxd0", "gmac_rxck", "gmac_rxctl", "gmac_clkin", "gmac_txd3", "gmac_txd2", "gmac_txd1", "gmac_txd0", "gmac_txck", "gmac_txctl", "gmac_mdc", "gmac_mdio", "gmac_ephy25m";
				allwinner,muxsel = <0x2>;
				allwinner,pull = <0xffffffff>;
				allwinner,drive = <0x3>;
				allwinner,data = <0xffffffff>;
			};

			twi0@0 {
				linux,phandle = <0xd0>;
				phandle = <0xd0>;
				allwinner,pins = "PH0", "PH1";
				allwinner,function = "twi0";
				allwinner,pname = "twi0_scl", "twi0_sda";
				allwinner,muxsel = <0x2>;
				allwinner,pull = <0xffffffff>;
				allwinner,drive = <0xffffffff>;
				allwinner,data = <0xffffffff>;
			};

			twi1@0 {
				linux,phandle = <0xd1>;
				phandle = <0xd1>;
				allwinner,pins = "PH2", "PH3";
				allwinner,function = "twi1";
				allwinner,pname = "twi1_scl", "twi1_sda";
				allwinner,muxsel = <0x2>;
				allwinner,pull = <0xffffffff>;
				allwinner,drive = <0xffffffff>;
				allwinner,data = <0xffffffff>;
			};

			twi2@0 {
				linux,phandle = <0xd2>;
				phandle = <0xd2>;
				allwinner,pins = "PI1", "PI2";
				allwinner,function = "twi2";
				allwinner,pname = "twi2_scl", "twi2_sda";
				allwinner,muxsel = <0x5>;
				allwinner,pull = <0xffffffff>;
				allwinner,drive = <0xffffffff>;
				allwinner,data = <0xffffffff>;
			};

			twi3@0 {
				linux,phandle = <0xd3>;
				phandle = <0xd3>;
				allwinner,pins = "PI8", "PI9";
				allwinner,function = "twi3";
				allwinner,pname = "twi3_scl", "twi3_sda";
				allwinner,muxsel = <0x5>;
				allwinner,pull = <0xffffffff>;
				allwinner,drive = <0xffffffff>;
				allwinner,data = <0xffffffff>;
			};

			uart0@0 {
				linux,phandle = <0xd4>;
				phandle = <0xd4>;
				allwinner,pins = "PB9", "PB10";
				allwinner,function = "uart0";
				allwinner,pname = "uart0_tx", "uart0_rx";
				allwinner,muxsel = <0x2>;
				allwinner,pull = <0x1>;
				allwinner,drive = <0xffffffff>;
				allwinner,data = <0xffffffff>;
			};

			uart1@0 {
				linux,phandle = <0xd5>;
				phandle = <0xd5>;
				allwinner,pins = "PG6", "PG7", "PG8", "PG9";
				allwinner,function = "uart1";
				allwinner,pname = "uart1_tx", "uart1_rx", "uart1_rts", "uart1_cts";
				allwinner,muxsel = <0x2>;
				allwinner,pull = <0x1>;
				allwinner,drive = <0xffffffff>;
				allwinner,data = <0xffffffff>;
			};

			uart1@1 {
				linux,phandle = <0xd6>;
				phandle = <0xd6>;
				allwinner,pins = "PG6", "PG7", "PG8", "PG9";
				allwinner,function = "uart1";
				allwinner,pname = "uart1_tx", "uart1_rx", "uart1_rts", "uart1_cts";
				allwinner,muxsel = <0x7>;
				allwinner,pull = <0x1>;
				allwinner,drive = <0xffffffff>;
				allwinner,data = <0xffffffff>;
			};

			uart2@0 {
				linux,phandle = <0xd7>;
				phandle = <0xd7>;
				allwinner,pins = "PB0", "PB1";
				allwinner,function = "uart2";
				allwinner,pname = "uart2_tx", "uart2_rx";
				allwinner,muxsel = <0x2>;
				allwinner,pull = <0x1>;
				allwinner,drive = <0xffffffff>;
				allwinner,data = <0xffffffff>;
			};

			uart2@1 {
				linux,phandle = <0xd8>;
				phandle = <0xd8>;
				allwinner,pins = "PB0", "PB1";
				allwinner,function = "uart2";
				allwinner,pname = "uart2_tx", "uart2_rx";
				allwinner,muxsel = <0x7>;
				allwinner,pull = <0x1>;
				allwinner,drive = <0xffffffff>;
				allwinner,data = <0xffffffff>;
			};

			uart4@0 {
				linux,phandle = <0xd9>;
				phandle = <0xd9>;
				allwinner,pins = "PH0", "PH1";
				allwinner,function = "uart4";
				allwinner,pname = "uart4_tx", "uart4_rx";
				allwinner,muxsel = <0x2>;
				allwinner,pull = <0x1>;
				allwinner,drive = <0xffffffff>;
				allwinner,data = <0xffffffff>;
			};

			uart4@1 {
				linux,phandle = <0xda>;
				phandle = <0xda>;
				allwinner,pins = "PH0", "PH1";
				allwinner,function = "uart4";
				allwinner,pname = "uart4_tx", "uart4_rx";
				allwinner,muxsel = <0x7>;
				allwinner,pull = <0x1>;
				allwinner,drive = <0xffffffff>;
				allwinner,data = <0xffffffff>;
			};

			spi0@0 {
				linux,phandle = <0xdb>;
				phandle = <0xdb>;
				allwinner,pins = "PC15", "PC16";
				allwinner,function = "spi0";
				allwinner,pname = "spi0_cs0", "spi0_cs1";
				allwinner,muxsel = <0x4>;
				allwinner,pull = <0x1>;
				allwinner,drive = <0xffffffff>;
				allwinner,data = <0xffffffff>;
			};

			spi0@1 {
				linux,phandle = <0xdc>;
				phandle = <0xdc>;
				allwinner,pins = "PC0", "PC2", "PC3", "PC6", "PC7";
				allwinner,function = "spi0";
				allwinner,pname = "spi0_sclk", "spi0_mosi", "spi0_miso", "spi0_hold", "spi0_wp";
				allwinner,muxsel = <0x4>;
				allwinner,pull = <0xffffffff>;
				allwinner,drive = <0xffffffff>;
				allwinner,data = <0xffffffff>;
			};

			spi1@0 {
				linux,phandle = <0xdd>;
				phandle = <0xdd>;
				allwinner,pins = "PH7", "PH8";
				allwinner,function = "spi1";
				allwinner,pname = "spi1_cs0", "spi1_cs1";
				allwinner,muxsel = <0x3>;
				allwinner,pull = <0x1>;
				allwinner,drive = <0xffffffff>;
				allwinner,data = <0xffffffff>;
			};

			spi1@1 {
				linux,phandle = <0xde>;
				phandle = <0xde>;
				allwinner,pins = "PH15", "PH14", "PH6";
				allwinner,function = "spi1";
				allwinner,pname = "spi1_sclk", "spi1_mosi", "spi1_miso";
				allwinner,muxsel = <0x3>;
				allwinner,pull = <0xffffffff>;
				allwinner,drive = <0xffffffff>;
				allwinner,data = <0xffffffff>;
			};

			spi2@0 {
				linux,phandle = <0xdf>;
				phandle = <0xdf>;
				allwinner,pins = "PI4";
				allwinner,function = "spi2";
				allwinner,pname = "spi2_cs0";
				allwinner,muxsel = <0x4>;
				allwinner,pull = <0x1>;
				allwinner,drive = <0xffffffff>;
				allwinner,data = <0xffffffff>;
			};

			spi2@1 {
				linux,phandle = <0xe0>;
				phandle = <0xe0>;
				allwinner,pins = "PI1", "PI2", "PI3";
				allwinner,function = "spi2";
				allwinner,pname = "spi2_sclk", "spi2_mosi", "spi2_miso";
				allwinner,muxsel = <0x4>;
				allwinner,pull = <0xffffffff>;
				allwinner,drive = <0xffffffff>;
				allwinner,data = <0xffffffff>;
			};

			spi3@0 {
				linux,phandle = <0xe1>;
				phandle = <0xe1>;
				allwinner,pins = "PI11";
				allwinner,function = "spi3";
				allwinner,pname = "spi3_cs0";
				allwinner,muxsel = <0x4>;
				allwinner,pull = <0x1>;
				allwinner,drive = <0xffffffff>;
				allwinner,data = <0xffffffff>;
			};

			spi3@1 {
				linux,phandle = <0xe2>;
				phandle = <0xe2>;
				allwinner,pins = "PI8", "PI9", "PI10";
				allwinner,function = "spi3";
				allwinner,pname = "spi3_sclk", "spi3_mosi", "spi3_miso";
				allwinner,muxsel = <0x4>;
				allwinner,pull = <0xffffffff>;
				allwinner,drive = <0xffffffff>;
				allwinner,data = <0xffffffff>;
			};

			nand0@0 {
				linux,phandle = <0xe4>;
				phandle = <0xe4>;
				allwinner,pins = "PC0", "PC1", "PC2", "PC4", "PC6", "PC7", "PC8", "PC9", "PC10", "PC11", "PC12", "PC13", "PC14";
				allwinner,function = "nand0";
				allwinner,pname = "nand0_we", "nand0_ale", "nand0_cle", "nand0_nre", "nand0_d0", "nand0_d1", "nand0_d2", "nand0_d3", "nand0_d4", "nand0_d5", "nand0_d6", "nand0_d7", "nand0_ndqs";
				allwinner,muxsel = <0x2>;
				allwinner,pull = <0x0>;
				allwinner,drive = <0x1>;
				allwinner,data = <0xffffffff>;
			};

			nand0@1 {
				linux,phandle = <0xe5>;
				phandle = <0xe5>;
				allwinner,pins = "PC3", "PC5", "PC15", "PC16";
				allwinner,function = "nand0";
				allwinner,pname = "nand0_ce0", "nand0_rb0", "nand0_ce1", "nand0_rb1";
				allwinner,muxsel = <0x2>;
				allwinner,pull = <0x1>;
				allwinner,drive = <0x1>;
				allwinner,data = <0xffffffff>;
			};

			hdmi@0 {
				linux,phandle = <0xe6>;
				phandle = <0xe6>;
				allwinner,pins = "PH11", "PH12", "PH13";
				allwinner,function = "hdmi";
				allwinner,pname = "hdmi_io_0", "hdmi_io_1", "hdmi_io_2";
				allwinner,muxsel = <0x2>;
				allwinner,pull = <0x0>;
				allwinner,drive = <0xffffffff>;
				allwinner,data = <0xffffffff>;
			};

			hdmi@1 {
				linux,phandle = <0xe7>;
				phandle = <0xe7>;
				allwinner,pins = "PH11", "PH12", "PH13";
				allwinner,function = "hdmi";
				allwinner,pname = "hdmi_io_0", "hdmi_io_1", "hdmi_io_2";
				allwinner,muxsel = <0x7>;
				allwinner,pull = <0x0>;
				allwinner,drive = <0xffffffff>;
				allwinner,data = <0xffffffff>;
			};

			pwm0@0 {
				linux,phandle = <0xe8>;
				phandle = <0xe8>;
				allwinner,pins = "PG6";
				allwinner,function = "pwm0";
				allwinner,pname = "pwm_positive";
				allwinner,muxsel = <0x2>;
				allwinner,pull = <0x0>;
				allwinner,drive = <0xffffffff>;
				allwinner,data = <0xffffffff>;
			};

			pwm0@1 {
				linux,phandle = <0xe9>;
				phandle = <0xe9>;
				allwinner,pins = "PG6";
				allwinner,function = "pwm0";
				allwinner,pname = "pwm_positive";
				allwinner,muxsel = <0x7>;
				allwinner,pull = <0x0>;
				allwinner,drive = <0xffffffff>;
				allwinner,data = <0xffffffff>;
			};

			pwm1@0 {
				linux,phandle = <0xea>;
				phandle = <0xea>;
				allwinner,pins = "PG7";
				allwinner,function = "pwm1";
				allwinner,pname = "pwm_positive";
				allwinner,muxsel = <0x2>;
				allwinner,pull = <0x0>;
				allwinner,drive = <0xffffffff>;
				allwinner,data = <0xffffffff>;
			};

			pwm1@1 {
				linux,phandle = <0xeb>;
				phandle = <0xeb>;
				allwinner,pins = "PG7";
				allwinner,function = "pwm1";
				allwinner,pname = "pwm_positive";
				allwinner,muxsel = <0x7>;
				allwinner,pull = <0x0>;
				allwinner,drive = <0xffffffff>;
				allwinner,data = <0xffffffff>;
			};

			pwm8@0 {
				linux,phandle = <0xec>;
				phandle = <0xec>;
				allwinner,pins = "PD22";
				allwinner,function = "pwm8";
				allwinner,pname = "pwm_positive";
				allwinner,muxsel = <0x2>;
				allwinner,pull = <0x0>;
				allwinner,drive = <0xffffffff>;
				allwinner,data = <0xffffffff>;
			};

			pwm8@1 {
				linux,phandle = <0xed>;
				phandle = <0xed>;
				allwinner,pins = "PD22";
				allwinner,function = "pwm8";
				allwinner,pname = "pwm_positive";
				allwinner,muxsel = <0x7>;
				allwinner,pull = <0x0>;
				allwinner,drive = <0xffffffff>;
				allwinner,data = <0xffffffff>;
			};

			csi_cci0@2 {
				linux,phandle = <0xf0>;
				phandle = <0xf0>;
				allwinner,pins = "PE16", "PE17";
				allwinner,function = "csi_cci0";
				allwinner,pname = "csi_cci0_sck", "csi_cci0_sda";
				allwinner,muxsel = <0x2>;
				allwinner,pull = <0xffffffff>;
				allwinner,drive = <0xffffffff>;
				allwinner,data = <0xffffffff>;
			};

			csi_cci1@2 {
				linux,phandle = <0xf1>;
				phandle = <0xf1>;
				allwinner,pins = "PJ16", "PJ17";
				allwinner,function = "csi_cci1";
				allwinner,pname = "csi_cci3_sck", "csi_cci3_sda";
				allwinner,muxsel = <0x2>;
				allwinner,pull = <0xffffffff>;
				allwinner,drive = <0xffffffff>;
				allwinner,data = <0xffffffff>;
			};

			csi_cci2@2 {
				linux,phandle = <0xf2>;
				phandle = <0xf2>;
				allwinner,pins = "PI1", "PI2";
				allwinner,function = "csi_cci2";
				allwinner,pname = "csi_cci1_sck", "csi_cci1_sda";
				allwinner,muxsel = <0x3>;
				allwinner,pull = <0xffffffff>;
				allwinner,drive = <0xffffffff>;
				allwinner,data = <0xffffffff>;
			};

			csi_cci3@2 {
				linux,phandle = <0xf3>;
				phandle = <0xf3>;
				allwinner,pins = "PI8", "PI9";
				allwinner,function = "csi_cci3";
				allwinner,pname = "csi_cci3_sck", "csi_cci3_sda";
				allwinner,muxsel = <0x3>;
				allwinner,pull = <0xffffffff>;
				allwinner,drive = <0xffffffff>;
				allwinner,data = <0xffffffff>;
			};

			csi2@0 {
				linux,phandle = <0xf4>;
				phandle = <0xf4>;
				allwinner,pins = "PE0", "PE2", "PE3", "PE4", "PE5", "PE6", "PE7", "PE8", "PE9", "PE10", "PE11", "PE12", "PE13", "PE14", "PE15";
				allwinner,function = "csi2";
				allwinner,pname = "csi2_pck", "csi2_hsync", "csi2_vsync", "csi2_d0", "csi2_d1", "csi2_d2", "csi2_d3", "csi2_d4", "csi2_d5", "csi2_d6", "csi2_d7", "csi2_d8", "csi2_d9", "csi2_d10", "csi2_d11";
				allwinner,muxsel = <0x2>;
				allwinner,pull = <0xffffffff>;
				allwinner,drive = <0xffffffff>;
				allwinner,data = <0xffffffff>;
			};

			csi3@0 {
				linux,phandle = <0xf5>;
				phandle = <0xf5>;
				allwinner,pins = "PJ0", "PJ2", "PJ3", "PJ4", "PJ5", "PJ6", "PJ7", "PJ8", "PJ9", "PJ10", "PJ11", "PJ12", "PJ13", "PJ14", "PJ15";
				allwinner,function = "csi3";
				allwinner,pname = "csi3_pck", "csi3_hsync", "csi3_vsync", "csi3_d0", "csi3_d1", "csi3_d2", "csi3_d3", "csi3_d4", "csi3_d5", "csi3_d6", "csi3_d7", "csi3_d8", "csi3_d9", "csi3_d10", "csi3_d11";
				allwinner,muxsel = <0x2>;
				allwinner,pull = <0xffffffff>;
				allwinner,drive = <0xffffffff>;
				allwinner,data = <0xffffffff>;
			};

			sdc0@0 {
				linux,phandle = <0xf6>;
				phandle = <0xf6>;
				allwinner,pins = "PF0", "PF1", "PF2", "PF3", "PF4", "PF5";
				allwinner,function = "sdc0";
				allwinner,pname = "sdc0_d1", "sdc0_d0", "sdc0_clk", "sdc0_cmd", "sdc0_d3", "sdc0_d2";
				allwinner,muxsel = <0x2>;
				allwinner,pull = <0x1>;
				allwinner,drive = <0x3>;
				allwinner,data = <0xffffffff>;
			};

			sdc1@0 {
				linux,phandle = <0xf7>;
				phandle = <0xf7>;
				allwinner,pins = "PG0", "PG1", "PG2", "PG3", "PG4", "PG5";
				allwinner,function = "sdc1";
				allwinner,pname = "sdc1_clk", "sdc1_cmd", "sdc1_d0", "sdc1_d1", "sdc1_d2", "sdc1_d3";
				allwinner,muxsel = <0x2>;
				allwinner,pull = <0x1>;
				allwinner,drive = <0x3>;
				allwinner,data = <0xffffffff>;
			};

			sdc2@0 {
				linux,phandle = <0xf8>;
				phandle = <0xf8>;
				allwinner,pins = "PC4", "PC5", "PC6", "PC7", "PC8", "PC9", "PC10", "PC11", "PC12", "PC13", "PC14", "PC1";
				allwinner,function = "sdc2";
				allwinner,pname = "sdc2_clk", "sdc2_cmd", "sdc2_d0", "sdc2_d1", "sdc2_d2", "sdc2_d3", "sdc2_d4", "sdc2_d5", "sdc2_d6", "sdc2_d7", "sdc2_emmc_rst", "sdc2_ds";
				allwinner,muxsel = <0x3>;
				allwinner,pull = <0x1>;
				allwinner,drive = <0x3>;
				allwinner,data = <0xffffffff>;
			};

			Vdevice@0 {
				linux,phandle = <0xfc>;
				phandle = <0xfc>;
				allwinner,pins = "PB1", "PB2";
				allwinner,function = "Vdevice";
				allwinner,pname = "Vdevice_0", "Vdevice_1";
				allwinner,muxsel = <0x4>;
				allwinner,pull = <0x1>;
				allwinner,drive = <0x2>;
				allwinner,data = <0xffffffff>;
			};
		};

		dma-controller@03002000 {
			compatible = "allwinner,sun8i-dma";
			reg = <0x0 0x3002000 0x0 0x1000>;
			interrupts = <0x0 0xa 0x4>;
			clocks = <0x11>;
			#dma-cells = <0x1>;
		};

		mbus-controller@04002000 {
			compatible = "allwinner,sun8i-mbus";
			reg = <0x0 0x4002000 0x0 0x1000>;
			#mbus-cells = <0x1>;
		};

		arisc {
			compatible = "allwinner,sunxi-arisc";
			#address-cells = <0x2>;
			#size-cells = <0x2>;
			clocks = <0x12 0x13 0x6 0x2>;
			clock-names = "losc", "iosc", "hosc", "pll_periph0";
			powchk_used = <0x0>;
			power_reg = <0x2309621>;
			system_power = <0x32>;
		};

		arisc_space {
			compatible = "allwinner,arisc_space";
			space1 = <0x100000 0x0 0x14000>;
			space2 = <0x48100000 0x18000 0x4000>;
			space3 = <0x48104000 0x0 0x1000>;
			space4 = <0x48105000 0x0 0x1000>;
		};

		standby_space {
			compatible = "allwinner,standby_space";
			space1 = <0x40020000 0x0 0x800>;
		};

		msgbox@3003000 {
			compatible = "allwinner,msgbox";
			clocks = <0x14>;
			clock-names = "clk_msgbox";
			reg = <0x0 0x3003000 0x0 0x1000>;
			interrupts = <0x0 0xb 0x1>;
			status = "okay";
		};

		hwspinlock@3004000 {
			compatible = "allwinner,sunxi-hwspinlock";
			clocks = <0x15 0x16>;
			clock-names = "clk_hwspinlock_rst", "clk_hwspinlock_bus";
			reg = <0x0 0x3004000 0x0 0x1000>;
			num-locks = <0x8>;
			status = "okay";
		};

		s_cir@07040000 {
			compatible = "allwinner,s_cir";
			reg = <0x0 0x7040000 0x0 0x400>;
			interrupts = <0x0 0x73 0x4>;
			pinctrl-names = "default";
			pinctrl-0 = <0x17>;
			clocks = <0x6 0x18>;
			supply = [00];
			supply_vol = [00];
			status = "disabled";
			device_type = "s_cir0";
			ir_power_key_code = <0x0>;
			ir_protocol_used = <0x0>;
		};

		s_uart@7080000 {
			compatible = "allwinner,s_uart";
			reg = <0x0 0x7080000 0x0 0x400>;
			interrupts = <0x0 0x83 0x4>;
			pinctrl-names = "default";
			status = "okay";
			device_type = "s_uart0";
			s_uart_used = <0x0>;
			pinctrl-0 = <0xf9>;
		};

		s_rsb@7083000 {
			compatible = "allwinner,s_rsb";
			reg = <0x0 0x7083000 0x0 0x300>;
			interrupts = <0x0 0x8c 0x4>;
			pinctrl-names = "default";
			pinctrl-0 = <0x1a>;
			status = "okay";
		};

		s_twi@7081400 {
			compatible = "allwinner,s_twi";
			reg = <0x0 0x7081400 0x0 0x400>;
			interrupts = <0x0 0x84 0x4>;
			pinctrl-names = "default";
			pinctrl-0 = <0x1b>;
			status = "okay";
		};

		s_twi@7081800 {
			compatible = "allwinner,s_twi";
			reg = <0x0 0x7081800 0x0 0x400>;
			interrupts = <0x0 0x85 0x4>;
			pinctrl-names = "default";
			pinctrl-0 = <0x1b>;
			status = "okay";
		};

		s_jtag0 {
			compatible = "allwinner,s_jtag";
			pinctrl-names = "default";
			status = "disable";
			device_type = "s_jtag0";
			s_jtag_used = <0x0>;
			pinctrl-0 = <0xfb>;
		};

		s_cpuscfg@0x7000400 {
			compatible = "allwinner,s_cpuscfg";
			reg = <0x0 0x7000400 0x0 0x800>;
			status = "okay";
		};

		box_start_os0 {
			compatible = "allwinner,box_start_os";
			start_type = <0x0>;
			irkey_used = <0x0>;
			pmukey_used = <0x0>;
			pmukey_num = <0x0>;
			led_power = <0x0>;
			led_state = <0x0>;
			status = "disable";
		};

		timer@03009000 {
			compatible = "allwinner,sun4i-a10-timer";
			device_type = "soc_timer";
			reg = <0x0 0x3009000 0x0 0x90>;
			interrupts = <0x0 0x3c 0x1>;
			clocks = <0x12 0x6>;
		};

		rtc@07000000 {
			compatible = "allwinner,sun8i-rtc", "allwinner,sunxi-rtc";
			device_type = "rtc";
			reg = <0x0 0x7000000 0x0 0x400>;
			interrupts = <0x0 0x6b 0x4>;
			gpr_offset = <0x100>;
			gpr_len = <0x8>;
		};

		watchdog@030090a0 {
			compatible = "allwinner,sun6i-a31-wdt";
			reg = <0x0 0x30090a0 0x0 0x20>;
			interrupts = <0x0 0xe 0x4>;
		};

		eve@01500000 {
			compatible = "allwinner,sunxi-aie-eve";
			reg = <0x0 0x1500000 0x0 0xff>;
			interrupts = <0x0 0x16 0x4>;
			clocks = <0x1d 0x1e>;
		};

		cve@01600000 {
			compatible = "allwinner,sunxi-aie-cve";
			reg = <0x0 0x1600000 0x0 0xff 0x0 0x3001000 0x0 0x80f>;
			interrupts = <0x0 0x17 0x4>;
			clocks = <0x1f 0x20>;
		};

		ise@01c10000 {
			compatible = "allwinner,sunxi-ise";
			reg = <0x0 0x1c10000 0x0 0x1000 0x0 0x3001000 0x0 0x800>;
			interrupts = <0x0 0x18 0x4>;
			clocks = <0x21 0x22>;
		};

		ve@01c0e000 {
			compatible = "allwinner,sunxi-cedar-ve";
			reg = <0x0 0x1c0e000 0x0 0x1000 0x0 0x3000000 0x0 0x10 0x0 0x3001000 0x0 0x1000>;
			interrupts = <0x0 0x19 0x4>;
			clocks = <0x23 0x24>;
		};

		uart@05000000 {
			compatible = "allwinner,sun8i-uart";
			device_type = "uart0";
			reg = <0x0 0x5000000 0x0 0x400>;
			interrupts = <0x0 0x31 0x4>;
			clocks = <0x25>;
			pinctrl-names = "default", "sleep";
			pinctrl-1 = <0x27>;
			uart0_port = <0x0>;
			uart0_type = <0x2>;
			status = "okay";
			pinctrl-0 = <0xd4>;
		};

		uart@05000400 {
			compatible = "allwinner,sun8i-uart";
			device_type = "uart1";
			reg = <0x0 0x5000400 0x0 0x400>;
			interrupts = <0x0 0x32 0x4>;
			clocks = <0x28>;
			pinctrl-names = "default", "sleep";
			uart1_port = <0x1>;
			uart1_type = <0x4>;
			status = "disabled";
			pinctrl-0 = <0xd5>;
			uart1_bt = <0x1>;
			pinctrl-1 = <0xd6>;
		};

		uart@05000800 {
			compatible = "allwinner,sun8i-uart";
			device_type = "uart2";
			reg = <0x0 0x5000800 0x0 0x400>;
			interrupts = <0x0 0x33 0x4>;
			clocks = <0x2b>;
			pinctrl-names = "default", "sleep";
			uart2_port = <0x2>;
			uart2_type = <0x2>;
			status = "okay";
			pinctrl-0 = <0xd7>;
			pinctrl-1 = <0xd8>;
		};

		uart@05000c00 {
			compatible = "allwinner,sun8i-uart";
			device_type = "uart3";
			reg = <0x0 0x5000c00 0x0 0x400>;
			interrupts = <0x0 0x34 0x4>;
			clocks = <0x2e>;
			pinctrl-names = "default", "sleep";
			pinctrl-0 = <0x2f>;
			pinctrl-1 = <0x30>;
			uart3_port = <0x3>;
			uart3_type = <0x4>;
			status = "disabled";
		};

		uart@05001000 {
			compatible = "allwinner,sun8i-uart";
			device_type = "uart4";
			reg = <0x0 0x5001000 0x0 0x400>;
			interrupts = <0x0 0x35 0x4>;
			clocks = <0x31>;
			pinctrl-names = "default", "sleep";
			uart4_port = <0x4>;
			uart4_type = <0x2>;
			status = "okay";
			pinctrl-0 = <0xd9>;
			pinctrl-1 = <0xda>;
		};

		twi@0x05002000 {
			#address-cells = <0x1>;
			#size-cells = <0x0>;
			compatible = "allwinner,sun8i-twi";
			device_type = "twi0";
			reg = <0x0 0x5002000 0x0 0x400>;
			interrupts = <0x0 0x29 0x4>;
			clocks = <0x34>;
			clock-frequency = <0x61a80>;
			pinctrl-names = "default", "sleep";
			pinctrl-1 = <0x36>;
			status = "disabled";
			pinctrl-0 = <0xd0>;
		};

		twi@0x05002400 {
			#address-cells = <0x1>;
			#size-cells = <0x0>;
			compatible = "allwinner,sun8i-twi";
			device_type = "twi1";
			reg = <0x0 0x5002400 0x0 0x400>;
			interrupts = <0x0 0x2a 0x4>;
			clocks = <0x37>;
			clock-frequency = <0x186a0>;
			pinctrl-names = "default", "sleep";
			pinctrl-1 = <0x39>;
			status = "disabled";
			pinctrl-0 = <0xd1>;
		};

		twi@0x05002800 {
			#address-cells = <0x1>;
			#size-cells = <0x0>;
			compatible = "allwinner,sun8i-twi";
			device_type = "twi2";
			reg = <0x0 0x5002800 0x0 0x400>;
			interrupts = <0x0 0x2b 0x4>;
			clocks = <0x3a>;
			clock-frequency = <0x186a0>;
			pinctrl-names = "default", "sleep";
			pinctrl-1 = <0x3c>;
			status = "okay";
			pinctrl-0 = <0xd2>;
		};

		twi@0x05002c00 {
			#address-cells = <0x1>;
			#size-cells = <0x0>;
			compatible = "allwinner,sun8i-twi";
			device_type = "twi3";
			reg = <0x0 0x5002c00 0x0 0x400>;
			interrupts = <0x0 0x2c 0x4>;
			clocks = <0x3d>;
			clock-frequency = <0x186a0>;
			pinctrl-names = "default", "sleep";
			pinctrl-1 = <0x3f>;
			status = "disabled";
			pinctrl-0 = <0xd3>;
		};

		usbc0@0 {
			device_type = "usbc0";
			compatible = "allwinner,sunxi-otg-manager";
			usb_port_type = <0x2>;
			usb_detect_type = <0x1>;
			usb_det_vbus_gpio = "axp_ctrl";
			usb_drv_vbus_gpio = "axp_ctrl";
			usb_host_init_state = <0x0>;
			usb_regulator_io = "nocare";
			usb_wakeup_suspend = <0x0>;
			usb_luns = <0x3>;
			usb_serial_unique = <0x0>;
			usb_serial_number = "20080411";
			rndis_wceis = <0x1>;
			status = "okay";
			usb_detect_mode = <0x0>;
			usb_id_gpio = <0x4f 0x1 0x4 0x0 0x1 0xffffffff 0xffffffff>;
		};

		udc-controller@0x05100000 {
			compatible = "allwinner,sunxi-udc";
			reg = <0x0 0x5100000 0x0 0x1000 0x0 0x0 0x0 0x100>;
			interrupts = <0x0 0x40 0x4>;
			clocks = <0x40 0x41>;
			status = "okay";
		};

		ehci0-controller@0x05101000 {
			compatible = "allwinner,sunxi-ehci0";
			reg = <0x0 0x5101000 0x0 0xfff 0x0 0x0 0x0 0x100 0x0 0x5100000 0x0 0x1000>;
			interrupts = <0x0 0x41 0x4>;
			clocks = <0x40 0x42>;
			hci_ctrl_no = <0x0>;
			status = "okay";
		};

		ohci0-controller@0x05101400 {
			compatible = "allwinner,sunxi-ohci0";
			reg = <0x0 0x5101000 0x0 0xfff 0x0 0x0 0x0 0x100 0x0 0x5100000 0x0 0x1000>;
			interrupts = <0x0 0x42 0x4>;
			clocks = <0x40 0x43 0x44 0x45 0x6 0x12>;
			hci_ctrl_no = <0x0>;
			status = "okay";
		};

		usbc1@0 {
			device_type = "usbc1";
			usb_host_init_state = <0x1>;
			usb_regulator_io = "nocare";
			usb_wakeup_suspend = <0x0>;
			status = "okay";
			usb_drv_vbus_gpio = <0x4f 0x1 0x5 0x0 0x1 0xffffffff 0xffffffff>;
		};

		ehci1-controller@0x05200000 {
			compatible = "allwinner,sunxi-ehci1";
			reg = <0x0 0x5200000 0x0 0xfff 0x0 0x0 0x0 0x100 0x0 0x5100000 0x0 0x1000>;
			interrupts = <0x0 0x43 0x4>;
			clocks = <0x46 0x47>;
			hci_ctrl_no = <0x1>;
			status = "okay";
		};

		ohci1-controller@0x05200400 {
			compatible = "allwinner,sunxi-ohci1";
			reg = <0x0 0x5200000 0x0 0xfff 0x0 0x0 0x0 0x100 0x0 0x5100000 0x0 0x1000>;
			interrupts = <0x0 0x44 0x4>;
			clocks = <0x46 0x48 0x49 0x45 0x6 0x12>;
			hci_ctrl_no = <0x1>;
			status = "okay";
		};

		codec@0x05096000 {
			compatible = "allwinner,sunxi-internal-codec";
			reg = <0x0 0x5096000 0x0 0x478 0x0 0x50967c0 0x0 0x4>;
			clocks = <0x4 0x4a>;
			pinctrl-names = "aif2-default", "aif3-default", "aif2-sleep", "aif3-sleep";
			pinctrl-0 = <0x4b>;
			pinctrl-1 = <0x4c>;
			pinctrl-2 = <0x4d>;
			pinctrl-3 = <0x4e>;
			gpio-spk = <0x4f 0x1 0x8 0x1 0x1 0x1 0x1>;
			headphonevol = <0x3b>;
			spkervol = <0x1b>;
			earpiecevol = <0x1e>;
			maingain = <0x4>;
			headsetmicgain = <0x4>;
			adcagc_cfg = <0x0>;
			adcdrc_cfg = <0x0>;
			adchpf_cfg = <0x0>;
			dacdrc_cfg = <0x0>;
			dachpf_cfg = <0x0>;
			aif1_lrlk_div = <0x40>;
			aif2_lrlk_div = <0x40>;
			aif2config = <0x0>;
			aif3config = <0x0>;
			pa_sleep_time = <0x15e>;
			dac_digital_vol = <0xa0a0>;
			status = "okay";
			linux,phandle = <0x5b>;
			phandle = <0x5b>;
			device_type = "codec";
		};

		i2s0-controller@0x05096000 {
			compatible = "allwinner,sunxi-internal-i2s";
			reg = <0x0 0x5096000 0x0 0x478>;
			clocks = <0x4 0x4a>;
			status = "okay";
			linux,phandle = <0x5a>;
			phandle = <0x5a>;
		};

		daudio@0x05090000 {
			compatible = "allwinner,sunxi-daudio";
			reg = <0x0 0x5090000 0x0 0x74>;
			clocks = <0x4 0x50>;
			pinctrl-names = "default", "sleep";
			pinctrl-0 = <0x51>;
			pinctrl-1 = <0x52>;
			pcm_lrck_period = <0x20>;
			slot_width_select = <0x20>;
			daudio_master = <0x4>;
			audio_format = <0x1>;
			signal_inversion = <0x1>;
			frametype = <0x0>;
			tdm_config = <0x1>;
			tdm_num = <0x0>;
			mclk_div = <0x0>;
			status = "disabled";
			linux,phandle = <0x5c>;
			phandle = <0x5c>;
			device_type = "daudio0";
			i2s0_mclk;
			i2s0_lrclk;
			i2s0_bclk;
			i2s0_dout0;
			i2s0_din;
		};

		daudio@0x05091000 {
			compatible = "allwinner,sunxi-tdmhdmi";
			reg = <0x0 0x5091000 0x0 0x74>;
			clocks = <0x4 0x53>;
			status = "okay";
			linux,phandle = <0x5d>;
			phandle = <0x5d>;
		};

		daudio@0x05092000 {
			compatible = "allwinner,sunxi-daudio";
			reg = <0x0 0x5092000 0x0 0x74>;
			clocks = <0x4 0x54>;
			pinctrl-names = "default", "sleep";
			pinctrl-0 = <0x55>;
			pinctrl-1 = <0x56>;
			pcm_lrck_period = <0x20>;
			slot_width_select = <0x20>;
			daudio_master = <0x4>;
			audio_format = <0x1>;
			signal_inversion = <0x1>;
			frametype = <0x0>;
			tdm_config = <0x1>;
			tdm_num = <0x2>;
			mclk_div = <0x0>;
			status = "disabled";
			linux,phandle = <0x5e>;
			phandle = <0x5e>;
			device_type = "daudio2";
		};

		dmic-controller@0x05095000 {
			compatible = "allwinner,sunxi-dmic";
			reg = <0x0 0x5095000 0x0 0x50>;
			clocks = <0x4 0x57>;
			pinctrl-names = "default", "sleep";
			pinctrl-0 = <0x58>;
			pinctrl-1 = <0x59>;
			status = "disabled";
			linux,phandle = <0x5f>;
			phandle = <0x5f>;
		};

		sound@0 {
			compatible = "allwinner,sunxi-codec-machine";
			interrupts = <0x0 0x1c 0x4>;
			sunxi,i2s-controller = <0x5a>;
			sunxi,audio-codec = <0x5b>;
			aif2fmt = <0x3>;
			aif3fmt = <0x3>;
			aif2master = <0x1>;
			hp_detect_case = <0x0>;
			status = "okay";
			device_type = "sndcodec";
		};

		sound@1 {
			compatible = "allwinner,sunxi-daudio0-machine";
			sunxi,daudio-controller = <0x5c>;
			status = "disabled";
			device_type = "snddaudio0";
		};

		sound@2 {
			compatible = "allwinner,sunxi-hdmi-machine";
			sunxi,hdmi-controller = <0x5d>;
			status = "okay";
		};

		sound@3 {
			compatible = "allwinner,sunxi-daudio2-machine";
			sunxi,daudio-controller = <0x5e>;
			status = "disabled";
			device_type = "snddaudio2";
		};

		sound@4 {
			compatible = "allwinner,sunxi-dmic-machine";
			sunxi,dmic-controller = <0x5f>;
			status = "okay";
		};

		sec-controller@0 {
			compatible = "allwinner,sunxi-sec";
			status = "okay";
			device_type = "sec";
			sec0;
			sec1 = <0x4f 0x7 0x5 0x1 0x0 0xffffffff 0xffffffff>;
			sec2 = <0x4f 0x7 0x6 0x1 0x0 0xffffffff 0xffffffff>;
			sec_power = "vcc-sec";
		};

		spi@05010000 {
			#address-cells = <0x1>;
			#size-cells = <0x0>;
			compatible = "allwinner,sun50i-spi";
			device_type = "spi0";
			reg = <0x0 0x5010000 0x0 0x1000>;
			interrupts = <0x0 0x36 0x4>;
			clocks = <0x2 0x60>;
			clock-frequency = <0xbebc200>;
			pinctrl-names = "default", "sleep";
			pinctrl-1 = <0x63>;
			spi0_cs_number = <0x2>;
			spi0_cs_bitmap = <0x3>;
			status = "okay";
			pinctrl-0 = <0xdb 0xdc>;

			spi_board0 {
				device_type = "spi_board0";
				compatible = "mx25l25645g";
				spi-max-frequency = <0x2faf080>;
				reg = <0x0>;
				spi-rx-bus-width = <0x1>;
				spi-tx-bus-width = <0x1>;
			};
		};

		spi@05011000 {
			#address-cells = <0x1>;
			#size-cells = <0x0>;
			compatible = "allwinner,sun50i-spi";
			device_type = "spi1";
			reg = <0x0 0x5011000 0x0 0x1000>;
			interrupts = <0x0 0x37 0x4>;
			clocks = <0x2 0x64>;
			clock-frequency = <0xbebc200>;
			pinctrl-names = "default", "sleep";
			pinctrl-1 = <0x67>;
			spi1_cs_number = <0x2>;
			spi1_cs_bitmap = <0x3>;
			status = "disabled";
			pinctrl-0 = <0xdd 0xde>;
		};

		spi@05012000 {
			#address-cells = <0x1>;
			#size-cells = <0x0>;
			compatible = "allwinner,sun50i-spi";
			device_type = "spi2";
			reg = <0x0 0x5012000 0x0 0x1000>;
			interrupts = <0x0 0x38 0x4>;
			clocks = <0x2 0x68>;
			clock-frequency = <0xbebc200>;
			pinctrl-names = "default", "sleep";
			pinctrl-1 = <0x6b>;
			spi2_cs_number = <0x1>;
			spi2_cs_bitmap = <0x1>;
			status = "disabled";
			pinctrl-0 = <0xdf 0xe0>;
		};

		spi@05013000 {
			#address-cells = <0x1>;
			#size-cells = <0x0>;
			compatible = "allwinner,sun50i-spi";
			device_type = "spi3";
			reg = <0x0 0x5013000 0x0 0x1000>;
			interrupts = <0x0 0x39 0x4>;
			clocks = <0x2 0x6c>;
			clock-frequency = <0xbebc200>;
			pinctrl-names = "default", "sleep";
			pinctrl-1 = <0x6f>;
			spi3_cs_number = <0x1>;
			spi3_cs_bitmap = <0x1>;
			status = "disabled";
			pinctrl-0 = <0xe1 0xe2>;
		};

		sdmmc@04022000 {
			compatible = "allwinner,sunxi-mmc-v4p5x";
			device_type = "sdc2";
			reg = <0x0 0x4022000 0x0 0x1000>;
			interrupts = <0x0 0x30 0x104>;
			clocks = <0x6 0x70 0x71 0x72 0x73>;
			clock-names = "osc24m", "pll_periph", "mmc", "ahb", "rst";
			pinctrl-names = "default", "sleep";
			pinctrl-1 = <0x75>;
			bus-width = <0x8>;
			cap-sd-highspeed;
			cap-mmc-highspeed;
			cap-wait-while-busy;
			mmc-high-capacity-erase-size;
			cap-erase;
			max-frequency = <0x2faf080>;
			sdc_tm4_sm0_freq0 = <0x0>;
			sdc_tm4_sm0_freq1 = <0x0>;
			sdc_tm4_sm1_freq0 = <0x0>;
			sdc_tm4_sm1_freq1 = <0x0>;
			sdc_tm4_sm2_freq0 = <0x0>;
			sdc_tm4_sm2_freq1 = <0x0>;
			sdc_tm4_sm3_freq0 = <0x5000000>;
			sdc_tm4_sm3_freq1 = <0x405>;
			sdc_tm4_sm4_freq0 = <0x50000>;
			sdc_tm4_sm4_freq1 = <0x408>;
			status = "disabled";
			non-removable;
			pinctrl-0 = <0xf8>;
			cd-gpios;
			sunxi-power-save-mode;
			sunxi-dis-signal-vol-sw;
			vmmc = "vcc-nand";
			vqmmc = "vcc33-pc";
			vdmmc = "none";
		};

		sdmmc@04020000 {
			compatible = "allwinner,sunxi-mmc-v4p1x";
			device_type = "sdc0";
			reg = <0x0 0x4020000 0x0 0x1000>;
			interrupts = <0x0 0x2e 0x104>;
			clocks = <0x6 0x70 0x76 0x77 0x78>;
			clock-names = "osc24m", "pll_periph", "mmc", "ahb", "rst";
			pinctrl-names = "default", "sleep";
			pinctrl-1 = <0x7a>;
			max-frequency = <0x8f0d180>;
			bus-width = <0x4>;
			cap-sd-highspeed;
			cap-mmc-highspeed;
			cap-wait-while-busy;
			status = "okay";
			pinctrl-0 = <0xf6>;
			cd-gpios = <0x4f 0x5 0x6 0x0 0x1 0x3 0xffffffff>;
			card-pwr-gpios = <0x4f 0x1 0x2 0x1 0x1 0x2 0xffffffff>;
			sunxi-power-save-mode;
			sd-uhs-sdr50;
			sd-uhs-ddr50;
			sd-uhs-sdr104;
			vmmc = "vcc-card";
			vqmmc = "vcc-pf";
			vdmmc = "vcc-pf";
		};

		sdmmc@04021000 {
			compatible = "allwinner,sunxi-mmc-v4p1x";
			device_type = "sdc1";
			reg = <0x0 0x4021000 0x0 0x1000>;
			interrupts = <0x0 0x2f 0x104>;
			clocks = <0x6 0x70 0x7b 0x7c 0x7d>;
			clock-names = "osc24m", "pll_periph", "mmc", "ahb", "rst";
			pinctrl-names = "default", "sleep";
			pinctrl-1 = <0x7f>;
			max-frequency = <0x8f0d180>;
			bus-width = <0x4>;
			cap-sd-highspeed;
			cap-mmc-highspeed;
			cap-wait-while-busy;
			sunxi-dly-52M-ddr4 = <0x1 0x0 0x0 0x0 0x2>;
			sunxi-dly-104M = <0x1 0x0 0x0 0x0 0x1>;
			sunxi-dly-208M = <0x1 0x0 0x0 0x0 0x1>;
			status = "disabled";
			pinctrl-0 = <0xf7>;
			sd-uhs-sdr50;
			sd-uhs-ddr50;
			sd-uhs-sdr104;
			cap-sdio-irq;
			keep-power-in-suspend;
			ignore-pm-notify;
		};

		disp@01000000 {
			compatible = "allwinner,sunxi-disp";
			reg = <0x0 0x1000000 0x0 0x3fffff 0x0 0x6510000 0x0 0xfff 0x0 0x6511000 0x0 0xfff 0x0 0x6515000 0x0 0xfff 0x0 0x6504000 0x0 0x2000>;
			interrupts = <0x0 0x3e 0x104 0x0 0x3f 0x104 0x0 0x2d 0x104>;
			clocks = <0x8 0x80 0xe 0x81 0xd 0x82 0xc>;
			boot_disp = <0x0>;
			fb_base = <0x0>;
			status = "okay";
			device_type = "disp";
			disp_init_enable = <0x1>;
			disp_mode = <0x0>;
			screen0_output_type = <0x1>;
			screen0_output_mode = <0x4>;
			screen1_output_type = <0x1>;
			screen1_output_mode = <0x4>;
			disp_rotation_used = <0x1>;
			degree0 = <0x1>;
			degree0_0 = <0x1>;
			fb0_format = <0x0>;
			fb0_width = <0x356>;
			fb0_height = <0x1e0>;
			fb1_format = <0x0>;
			fb1_width = <0x0>;
			fb1_height = <0x0>;
			lcd0_backlight = <0x32>;
			lcd1_backlight = <0x32>;
			lcd0_bright = <0x32>;
			lcd0_contrast = <0x32>;
			lcd0_saturation = <0x39>;
			lcd0_hue = <0x32>;
			lcd1_bright = <0x32>;
			lcd1_contrast = <0x32>;
			lcd1_saturation = <0x39>;
			lcd1_hue = <0x32>;
		};

		lcd0@01c0c000 {
			compatible = "allwinner,sunxi-lcd0";
			pinctrl-names = "active", "sleep";
			status = "okay";
			device_type = "lcd0";
			lcd_used = <0x1>;
			lcd_driver_name = "lx45fwu2406";
			lcd_bl_0_percent = <0x0>;
			lcd_bl_40_percent = <0x17>;
			lcd_bl_100_percent = <0x64>;
			lcd_backlight = <0x64>;
			lcd_if = <0x4>;
			lcd_x = <0x1e0>;
			lcd_y = <0x356>;
			lcd_width = <0x78>;
			lcd_height = <0xa0>;
			lcd_dclk_freq = <0x25>;
			lcd_pwm_used = <0x1>;
			lcd_pwm_ch = <0x0>;
			lcd_pwm_freq = <0xc350>;
			lcd_pwm_pol = <0x1>;
			lcd_pwm_max_limit = <0xff>;
			lcd_hbp = <0x10>;
			lcd_ht = <0x210>;
			lcd_hspw = <0x8>;
			lcd_vbp = <0x10>;
			lcd_vt = <0x378>;
			lcd_vspw = <0x2>;
			lcd_dsi_if = <0x0>;
			lcd_dsi_lane = <0x2>;
			lcd_dsi_format = <0x2>;
			lcd_dsi_te = <0x0>;
			lcd_dsi_eotp = <0x0>;
			lcd_frm = <0x0>;
			lcd_io_phase = <0x0>;
			lcd_hv_clk_phase = <0x0>;
			lcd_hv_sync_polarity = <0x0>;
			lcd_gamma_en = <0x0>;
			lcd_bright_curve_en = <0x0>;
			lcd_cmap_en = <0x0>;
			lcdgamma4iep = <0x16>;
			lcd_power = "vcc-lcd";
		};

		hdmi@06000000 {
			compatible = "allwinner,sunxi-hdmi";
			reg = <0x0 0x6000000 0x0 0x20000>;
			pinctrl-names = "active", "sleep";
			clocks = <0x83 0x84 0xa>;
			device_type = "hdmi";
			status = "okay";
			hdmi_hdcp_enable = <0x0>;
			hdmi_cts_compatibility = <0x0>;
			hdmi_power = "vcc18-hdmi";
			hdmi_io_regulator = "vdd09-hdmi";
			hdmi_io_regulator_val = <0x3e8>;
			pinctrl-0 = <0xe6>;
			pinctrl-1 = <0xe7>;
		};

		tv0@06524000 {
			compatible = "allwinner,sunxi-tv";
			reg = <0x0 0x6520000 0x0 0x100 0x0 0x6524000 0x0 0x3fc>;
			clocks = <0x85 0x86>;
			device_type = "tv0";
			pinctrl-names = "active", "sleep";
			status = "disabled";
		};

		tr@01000000 {
			compatible = "allwinner,sun50i-tr";
			reg = <0x0 0x1000000 0x0 0x200bc>;
			interrupts = <0x0 0x60 0x104>;
			clocks = <0x8>;
			status = "okay";
		};

		g2d@01480000 {
			compatible = "allwinner,sunxi-g2d";
			reg = <0x0 0x1480000 0x0 0xbffff>;
			interrupts = <0x0 0x15 0x104>;
			clocks = <0x87>;
			status = "okay";
		};

		pwm@0300a000 {
			compatible = "allwinner,sunxi-pwm";
			reg = <0x0 0x300a000 0x0 0x310>;
			clocks = <0x88>;
			pwm-number = <0x9>;
			pwm-base = <0x0>;
			pwms = <0x89 0x8a 0x8b 0x8c 0x8d 0x8e 0x8f 0x90 0x91>;
		};

		pwm0@0300a000 {
			compatible = "allwinner,sunxi-pwm0";
			pinctrl-names = "active", "sleep";
			reg_base = <0x300a000>;
			reg_peci_offset = <0x0>;
			reg_peci_shift = <0x0>;
			reg_peci_width = <0x1>;
			reg_pis_offset = <0x4>;
			reg_pis_shift = <0x0>;
			reg_pis_width = <0x1>;
			reg_crie_offset = <0x10>;
			reg_crie_shift = <0x0>;
			reg_crie_width = <0x1>;
			reg_cfie_offset = <0x10>;
			reg_cfie_shift = <0x1>;
			reg_cfie_width = <0x1>;
			reg_cris_offset = <0x14>;
			reg_cris_shift = <0x0>;
			reg_cris_width = <0x1>;
			reg_cfis_offset = <0x14>;
			reg_cfis_shift = <0x1>;
			reg_cfis_width = <0x1>;
			reg_clk_src_offset = <0x20>;
			reg_clk_src_shift = <0x7>;
			reg_clk_src_width = <0x2>;
			reg_bypass_offset = <0x20>;
			reg_bypass_shift = <0x5>;
			reg_bypass_width = <0x1>;
			reg_clk_gating_offset = <0x20>;
			reg_clk_gating_shift = <0x4>;
			reg_clk_gating_width = <0x1>;
			reg_clk_div_m_offset = <0x20>;
			reg_clk_div_m_shift = <0x0>;
			reg_clk_div_m_width = <0x4>;
			reg_pdzintv_offset = <0x30>;
			reg_pdzintv_shift = <0x8>;
			reg_pdzintv_width = <0x8>;
			reg_dz_en_offset = <0x30>;
			reg_dz_en_shift = <0x0>;
			reg_dz_en_width = <0x1>;
			reg_enable_offset = <0x40>;
			reg_enable_shift = <0x0>;
			reg_enable_width = <0x1>;
			reg_cap_en_offset = <0x44>;
			reg_cap_en_shift = <0x0>;
			reg_cap_en_width = <0x1>;
			reg_period_rdy_offset = <0x60>;
			reg_period_rdy_shift = <0xb>;
			reg_period_rdy_width = <0x1>;
			reg_pul_start_offset = <0x60>;
			reg_pul_start_shift = <0xa>;
			reg_pul_start_width = <0x1>;
			reg_mode_offset = <0x60>;
			reg_mode_shift = <0x9>;
			reg_mode_width = <0x1>;
			reg_act_sta_offset = <0x60>;
			reg_act_sta_shift = <0x8>;
			reg_act_sta_width = <0x1>;
			reg_prescal_offset = <0x60>;
			reg_prescal_shift = <0x0>;
			reg_prescal_width = <0x8>;
			reg_entire_offset = <0x64>;
			reg_entire_shift = <0x10>;
			reg_entire_width = <0x10>;
			reg_active_offset = <0x64>;
			reg_active_shift = <0x0>;
			reg_active_width = <0x10>;
			linux,phandle = <0x89>;
			phandle = <0x89>;
			device_type = "pwm0";
			pwm_used = <0x0>;
			pinctrl-0 = <0xe8>;
			pinctrl-1 = <0xe9>;
		};

		pwm1@0300a000 {
			compatible = "allwinner,sunxi-pwm1";
			pinctrl-names = "active", "sleep";
			reg_base = <0x300a000>;
			reg_peci_offset = <0x0>;
			reg_peci_shift = <0x1>;
			reg_peci_width = <0x1>;
			reg_pis_offset = <0x4>;
			reg_pis_shift = <0x1>;
			reg_pis_width = <0x1>;
			reg_crie_offset = <0x10>;
			reg_crie_shift = <0x2>;
			reg_crie_width = <0x1>;
			reg_cfie_offset = <0x10>;
			reg_cfie_shift = <0x3>;
			reg_cfie_width = <0x1>;
			reg_cris_offset = <0x14>;
			reg_cris_shift = <0x2>;
			reg_cris_width = <0x1>;
			reg_cfis_offset = <0x14>;
			reg_cfis_shift = <0x3>;
			reg_cfis_width = <0x1>;
			reg_clk_src_offset = <0x20>;
			reg_clk_src_shift = <0x7>;
			reg_clk_src_width = <0x2>;
			reg_bypass_offset = <0x20>;
			reg_bypass_shift = <0x6>;
			reg_bypass_width = <0x1>;
			reg_clk_gating_offset = <0x20>;
			reg_clk_gating_shift = <0x4>;
			reg_clk_gating_width = <0x1>;
			reg_clk_div_m_offset = <0x20>;
			reg_clk_div_m_shift = <0x0>;
			reg_clk_div_m_width = <0x4>;
			reg_pdzintv_offset = <0x30>;
			reg_pdzintv_shift = <0x8>;
			reg_pdzintv_width = <0x8>;
			reg_dz_en_offset = <0x30>;
			reg_dz_en_shift = <0x0>;
			reg_dz_en_width = <0x1>;
			reg_enable_offset = <0x40>;
			reg_enable_shift = <0x1>;
			reg_enable_width = <0x1>;
			reg_cap_en_offset = <0x44>;
			reg_cap_en_shift = <0x1>;
			reg_cap_en_width = <0x1>;
			reg_period_rdy_offset = <0x80>;
			reg_period_rdy_shift = <0xb>;
			reg_period_rdy_width = <0x1>;
			reg_pul_start_offset = <0x80>;
			reg_pul_start_shift = <0xa>;
			reg_pul_start_width = <0x1>;
			reg_mode_offset = <0x80>;
			reg_mode_shift = <0x9>;
			reg_mode_width = <0x1>;
			reg_act_sta_offset = <0x80>;
			reg_act_sta_shift = <0x8>;
			reg_act_sta_width = <0x1>;
			reg_prescal_offset = <0x80>;
			reg_prescal_shift = <0x0>;
			reg_prescal_width = <0x8>;
			reg_entire_offset = <0x84>;
			reg_entire_shift = <0x10>;
			reg_entire_width = <0x10>;
			reg_active_offset = <0x84>;
			reg_active_shift = <0x0>;
			reg_active_width = <0x10>;
			linux,phandle = <0x8a>;
			phandle = <0x8a>;
			device_type = "pwm1";
			pwm_used = <0x0>;
			pinctrl-0 = <0xea>;
			pinctrl-1 = <0xeb>;
		};

		pwm2@0300a000 {
			compatible = "allwinner,sunxi-pwm2";
			pinctrl-names = "active", "sleep";
			reg_base = <0x300a000>;
			reg_peci_offset = <0x0>;
			reg_peci_shift = <0x2>;
			reg_peci_width = <0x1>;
			reg_pis_offset = <0x4>;
			reg_pis_shift = <0x2>;
			reg_pis_width = <0x1>;
			reg_crie_offset = <0x10>;
			reg_crie_shift = <0x4>;
			reg_crie_width = <0x1>;
			reg_cfie_offset = <0x10>;
			reg_cfie_shift = <0x5>;
			reg_cfie_width = <0x1>;
			reg_cris_offset = <0x14>;
			reg_cris_shift = <0x4>;
			reg_cris_width = <0x1>;
			reg_cfis_offset = <0x14>;
			reg_cfis_shift = <0x5>;
			reg_cfis_width = <0x1>;
			reg_clk_src_offset = <0x24>;
			reg_clk_src_shift = <0x7>;
			reg_clk_src_width = <0x2>;
			reg_bypass_offset = <0x24>;
			reg_bypass_shift = <0x6>;
			reg_bypass_width = <0x1>;
			reg_clk_gating_offset = <0x24>;
			reg_clk_gating_shift = <0x4>;
			reg_clk_gating_width = <0x1>;
			reg_clk_div_m_offset = <0x24>;
			reg_clk_div_m_shift = <0x0>;
			reg_clk_div_m_width = <0x4>;
			reg_pdzintv_offset = <0x34>;
			reg_pdzintv_shift = <0x8>;
			reg_pdzintv_width = <0x8>;
			reg_dz_en_offset = <0x34>;
			reg_dz_en_shift = <0x0>;
			reg_dz_en_width = <0x1>;
			reg_enable_offset = <0x40>;
			reg_enable_shift = <0x2>;
			reg_enable_width = <0x1>;
			reg_cap_en_offset = <0x44>;
			reg_cap_en_shift = <0x2>;
			reg_cap_en_width = <0x1>;
			reg_period_rdy_offset = <0xa0>;
			reg_period_rdy_shift = <0xb>;
			reg_period_rdy_width = <0x1>;
			reg_pul_start_offset = <0xa0>;
			reg_pul_start_shift = <0xa>;
			reg_pul_start_width = <0x1>;
			reg_mode_offset = <0xa0>;
			reg_mode_shift = <0x9>;
			reg_mode_width = <0x1>;
			reg_act_sta_offset = <0xa0>;
			reg_act_sta_shift = <0x8>;
			reg_act_sta_width = <0x1>;
			reg_prescal_offset = <0xa0>;
			reg_prescal_shift = <0x0>;
			reg_prescal_width = <0x8>;
			reg_entire_offset = <0xa4>;
			reg_entire_shift = <0x10>;
			reg_entire_width = <0x10>;
			reg_active_offset = <0xa4>;
			reg_active_shift = <0x0>;
			reg_active_width = <0x10>;
			linux,phandle = <0x8b>;
			phandle = <0x8b>;
		};

		pwm3@0300a000 {
			compatible = "allwinner,sunxi-pwm3";
			pinctrl-names = "active", "sleep";
			reg_base = <0x300a000>;
			reg_peci_offset = <0x0>;
			reg_peci_shift = <0x3>;
			reg_peci_width = <0x1>;
			reg_pis_offset = <0x4>;
			reg_pis_shift = <0x4>;
			reg_pis_width = <0x1>;
			reg_crie_offset = <0x10>;
			reg_crie_shift = <0x6>;
			reg_crie_width = <0x1>;
			reg_cfie_offset = <0x10>;
			reg_cfie_shift = <0x7>;
			reg_cfie_width = <0x1>;
			reg_cris_offset = <0x14>;
			reg_cris_shift = <0x6>;
			reg_cris_width = <0x1>;
			reg_cfis_offset = <0x14>;
			reg_cfis_shift = <0x7>;
			reg_cfis_width = <0x1>;
			reg_clk_src_offset = <0x24>;
			reg_clk_src_shift = <0x7>;
			reg_clk_src_width = <0x2>;
			reg_bypass_offset = <0x24>;
			reg_bypass_shift = <0x6>;
			reg_bypass_width = <0x1>;
			reg_clk_gating_offset = <0x24>;
			reg_clk_gating_shift = <0x4>;
			reg_clk_gating_width = <0x1>;
			reg_clk_div_m_offset = <0x24>;
			reg_clk_div_m_shift = <0x0>;
			reg_clk_div_m_width = <0x4>;
			reg_pdzintv_offset = <0x34>;
			reg_pdzintv_shift = <0x8>;
			reg_pdzintv_width = <0x8>;
			reg_dz_en_offset = <0x34>;
			reg_dz_en_shift = <0x0>;
			reg_dz_en_width = <0x1>;
			reg_enable_offset = <0x40>;
			reg_enable_shift = <0x3>;
			reg_enable_width = <0x1>;
			reg_cap_en_offset = <0x44>;
			reg_cap_en_shift = <0x3>;
			reg_cap_en_width = <0x1>;
			reg_period_rdy_offset = <0xc0>;
			reg_period_rdy_shift = <0xb>;
			reg_period_rdy_width = <0x1>;
			reg_pul_start_offset = <0xc0>;
			reg_pul_start_shift = <0xa>;
			reg_pul_start_width = <0x1>;
			reg_mode_offset = <0xc0>;
			reg_mode_shift = <0x9>;
			reg_mode_width = <0x1>;
			reg_act_sta_offset = <0xc0>;
			reg_act_sta_shift = <0x8>;
			reg_act_sta_width = <0x1>;
			reg_prescal_offset = <0xc0>;
			reg_prescal_shift = <0x0>;
			reg_prescal_width = <0x8>;
			reg_entire_offset = <0xc4>;
			reg_entire_shift = <0x10>;
			reg_entire_width = <0x10>;
			reg_active_offset = <0xc4>;
			reg_active_shift = <0x0>;
			reg_active_width = <0x10>;
			linux,phandle = <0x8c>;
			phandle = <0x8c>;
		};

		pwm4@0300a000 {
			compatible = "allwinner,sunxi-pwm4";
			pinctrl-names = "active", "sleep";
			reg_base = <0x300a000>;
			reg_peci_offset = <0x0>;
			reg_peci_shift = <0x4>;
			reg_peci_width = <0x1>;
			reg_pis_offset = <0x4>;
			reg_pis_shift = <0x4>;
			reg_pis_width = <0x1>;
			reg_crie_offset = <0x10>;
			reg_crie_shift = <0x8>;
			reg_crie_width = <0x1>;
			reg_cfie_offset = <0x10>;
			reg_cfie_shift = <0x9>;
			reg_cfie_width = <0x1>;
			reg_cris_offset = <0x14>;
			reg_cris_shift = <0x8>;
			reg_cris_width = <0x1>;
			reg_cfis_offset = <0x14>;
			reg_cfis_shift = <0x9>;
			reg_cfis_width = <0x1>;
			reg_clk_src_offset = <0x28>;
			reg_clk_src_shift = <0x7>;
			reg_clk_src_width = <0x2>;
			reg_bypass_offset = <0x28>;
			reg_bypass_shift = <0x6>;
			reg_bypass_width = <0x1>;
			reg_clk_gating_offset = <0x28>;
			reg_clk_gating_shift = <0x4>;
			reg_clk_gating_width = <0x1>;
			reg_clk_div_m_offset = <0x28>;
			reg_clk_div_m_shift = <0x0>;
			reg_clk_div_m_width = <0x4>;
			reg_pdzintv_offset = <0x38>;
			reg_pdzintv_shift = <0x8>;
			reg_pdzintv_width = <0x8>;
			reg_dz_en_offset = <0x38>;
			reg_dz_en_shift = <0x0>;
			reg_dz_en_width = <0x1>;
			reg_enable_offset = <0x40>;
			reg_enable_shift = <0x4>;
			reg_enable_width = <0x1>;
			reg_cap_en_offset = <0x44>;
			reg_cap_en_shift = <0x4>;
			reg_cap_en_width = <0x1>;
			reg_period_rdy_offset = <0xe0>;
			reg_period_rdy_shift = <0xb>;
			reg_period_rdy_width = <0x1>;
			reg_pul_start_offset = <0xe0>;
			reg_pul_start_shift = <0xa>;
			reg_pul_start_width = <0x1>;
			reg_mode_offset = <0xe0>;
			reg_mode_shift = <0x9>;
			reg_mode_width = <0x1>;
			reg_act_sta_offset = <0xe0>;
			reg_act_sta_shift = <0x8>;
			reg_act_sta_width = <0x1>;
			reg_prescal_offset = <0xe0>;
			reg_prescal_shift = <0x0>;
			reg_prescal_width = <0x8>;
			reg_entire_offset = <0xe4>;
			reg_entire_shift = <0x10>;
			reg_entire_width = <0x10>;
			reg_active_offset = <0xe4>;
			reg_active_shift = <0x0>;
			reg_active_width = <0x10>;
			linux,phandle = <0x8d>;
			phandle = <0x8d>;
		};

		pwm5@0300a000 {
			compatible = "allwinner,sunxi-pwm5";
			pinctrl-names = "active", "sleep";
			reg_base = <0x300a000>;
			reg_peci_offset = <0x0>;
			reg_peci_shift = <0x5>;
			reg_peci_width = <0x1>;
			reg_pis_offset = <0x4>;
			reg_pis_shift = <0x5>;
			reg_pis_width = <0x1>;
			reg_crie_offset = <0x10>;
			reg_crie_shift = <0xa>;
			reg_crie_width = <0x1>;
			reg_cfie_offset = <0x10>;
			reg_cfie_shift = <0xb>;
			reg_cfie_width = <0x1>;
			reg_cris_offset = <0x14>;
			reg_cris_shift = <0xa>;
			reg_cris_width = <0x1>;
			reg_cfis_offset = <0x14>;
			reg_cfis_shift = <0xb>;
			reg_cfis_width = <0x1>;
			reg_clk_src_offset = <0x28>;
			reg_clk_src_shift = <0x7>;
			reg_clk_src_width = <0x2>;
			reg_bypass_offset = <0x28>;
			reg_bypass_shift = <0x6>;
			reg_bypass_width = <0x1>;
			reg_clk_gating_offset = <0x28>;
			reg_clk_gating_shift = <0x4>;
			reg_clk_gating_width = <0x1>;
			reg_clk_div_m_offset = <0x28>;
			reg_clk_div_m_shift = <0x0>;
			reg_clk_div_m_width = <0x4>;
			reg_pdzintv_offset = <0x38>;
			reg_pdzintv_shift = <0x8>;
			reg_pdzintv_width = <0x8>;
			reg_dz_en_offset = <0x38>;
			reg_dz_en_shift = <0x0>;
			reg_dz_en_width = <0x1>;
			reg_enable_offset = <0x40>;
			reg_enable_shift = <0x5>;
			reg_enable_width = <0x1>;
			reg_cap_en_offset = <0x44>;
			reg_cap_en_shift = <0x5>;
			reg_cap_en_width = <0x1>;
			reg_period_rdy_offset = <0x100>;
			reg_period_rdy_shift = <0xb>;
			reg_period_rdy_width = <0x1>;
			reg_pul_start_offset = <0x100>;
			reg_pul_start_shift = <0xa>;
			reg_pul_start_width = <0x1>;
			reg_mode_offset = <0x100>;
			reg_mode_shift = <0x9>;
			reg_mode_width = <0x1>;
			reg_act_sta_offset = <0x100>;
			reg_act_sta_shift = <0x8>;
			reg_act_sta_width = <0x1>;
			reg_prescal_offset = <0x100>;
			reg_prescal_shift = <0x0>;
			reg_prescal_width = <0x8>;
			reg_entire_offset = <0x104>;
			reg_entire_shift = <0x10>;
			reg_entire_width = <0x10>;
			reg_active_offset = <0x104>;
			reg_active_shift = <0x0>;
			reg_active_width = <0x10>;
			linux,phandle = <0x8e>;
			phandle = <0x8e>;
		};

		pwm6@0300a000 {
			compatible = "allwinner,sunxi-pwm6";
			pinctrl-names = "active", "sleep";
			reg_base = <0x300a000>;
			reg_peci_offset = <0x0>;
			reg_peci_shift = <0x6>;
			reg_peci_width = <0x1>;
			reg_pis_offset = <0x4>;
			reg_pis_shift = <0x6>;
			reg_pis_width = <0x1>;
			reg_crie_offset = <0x10>;
			reg_crie_shift = <0xc>;
			reg_crie_width = <0x1>;
			reg_cfie_offset = <0x10>;
			reg_cfie_shift = <0xd>;
			reg_cfie_width = <0x1>;
			reg_cris_offset = <0x14>;
			reg_cris_shift = <0xc>;
			reg_cris_width = <0x1>;
			reg_cfis_offset = <0x14>;
			reg_cfis_shift = <0xd>;
			reg_cfis_width = <0x1>;
			reg_clk_src_offset = <0x2c>;
			reg_clk_src_shift = <0x7>;
			reg_clk_src_width = <0x2>;
			reg_bypass_offset = <0x2c>;
			reg_bypass_shift = <0x6>;
			reg_bypass_width = <0x1>;
			reg_clk_gating_offset = <0x2c>;
			reg_clk_gating_shift = <0x4>;
			reg_clk_gating_width = <0x1>;
			reg_clk_div_m_offset = <0x2c>;
			reg_clk_div_m_shift = <0x0>;
			reg_clk_div_m_width = <0x4>;
			reg_pdzintv_offset = <0x3c>;
			reg_pdzintv_shift = <0x8>;
			reg_pdzintv_width = <0x8>;
			reg_dz_en_offset = <0x3c>;
			reg_dz_en_shift = <0x0>;
			reg_dz_en_width = <0x1>;
			reg_enable_offset = <0x40>;
			reg_enable_shift = <0x6>;
			reg_enable_width = <0x1>;
			reg_cap_en_offset = <0x44>;
			reg_cap_en_shift = <0x6>;
			reg_cap_en_width = <0x1>;
			reg_period_rdy_offset = <0x120>;
			reg_period_rdy_shift = <0xb>;
			reg_period_rdy_width = <0x1>;
			reg_pul_start_offset = <0x120>;
			reg_pul_start_shift = <0xa>;
			reg_pul_start_width = <0x1>;
			reg_mode_offset = <0x120>;
			reg_mode_shift = <0x9>;
			reg_mode_width = <0x1>;
			reg_act_sta_offset = <0x120>;
			reg_act_sta_shift = <0x8>;
			reg_act_sta_width = <0x1>;
			reg_prescal_offset = <0x120>;
			reg_prescal_shift = <0x0>;
			reg_prescal_width = <0x8>;
			reg_entire_offset = <0x124>;
			reg_entire_shift = <0x10>;
			reg_entire_width = <0x10>;
			reg_active_offset = <0x124>;
			reg_active_shift = <0x0>;
			reg_active_width = <0x10>;
			linux,phandle = <0x8f>;
			phandle = <0x8f>;
		};

		pwm7@0300a000 {
			compatible = "allwinner,sunxi-pwm7";
			pinctrl-names = "active", "sleep";
			reg_base = <0x300a000>;
			reg_peci_offset = <0x0>;
			reg_peci_shift = <0x7>;
			reg_peci_width = <0x1>;
			reg_pis_offset = <0x4>;
			reg_pis_shift = <0x7>;
			reg_pis_width = <0x1>;
			reg_crie_offset = <0x10>;
			reg_crie_shift = <0xe>;
			reg_crie_width = <0x1>;
			reg_cfie_offset = <0x10>;
			reg_cfie_shift = <0xf>;
			reg_cfie_width = <0x1>;
			reg_cris_offset = <0x14>;
			reg_cris_shift = <0xe>;
			reg_cris_width = <0x1>;
			reg_cfis_offset = <0x14>;
			reg_cfis_shift = <0xf>;
			reg_cfis_width = <0x1>;
			reg_clk_src_offset = <0x2c>;
			reg_clk_src_shift = <0x7>;
			reg_clk_src_width = <0x2>;
			reg_bypass_offset = <0x2c>;
			reg_bypass_shift = <0x6>;
			reg_bypass_width = <0x1>;
			reg_clk_gating_offset = <0x2c>;
			reg_clk_gating_shift = <0x4>;
			reg_clk_gating_width = <0x1>;
			reg_clk_div_m_offset = <0x2c>;
			reg_clk_div_m_shift = <0x0>;
			reg_clk_div_m_width = <0x4>;
			reg_pdzintv_offset = <0x3c>;
			reg_pdzintv_shift = <0x8>;
			reg_pdzintv_width = <0x8>;
			reg_dz_en_offset = <0x3c>;
			reg_dz_en_shift = <0x0>;
			reg_dz_en_width = <0x1>;
			reg_enable_offset = <0x40>;
			reg_enable_shift = <0x7>;
			reg_enable_width = <0x1>;
			reg_cap_en_offset = <0x44>;
			reg_cap_en_shift = <0x7>;
			reg_cap_en_width = <0x1>;
			reg_period_rdy_offset = <0x140>;
			reg_period_rdy_shift = <0xb>;
			reg_period_rdy_width = <0x1>;
			reg_pul_start_offset = <0x140>;
			reg_pul_start_shift = <0xa>;
			reg_pul_start_width = <0x1>;
			reg_mode_offset = <0x140>;
			reg_mode_shift = <0x9>;
			reg_mode_width = <0x1>;
			reg_act_sta_offset = <0x140>;
			reg_act_sta_shift = <0x8>;
			reg_act_sta_width = <0x1>;
			reg_prescal_offset = <0x140>;
			reg_prescal_shift = <0x0>;
			reg_prescal_width = <0x8>;
			reg_entire_offset = <0x144>;
			reg_entire_shift = <0x10>;
			reg_entire_width = <0x10>;
			reg_active_offset = <0x144>;
			reg_active_shift = <0x0>;
			reg_active_width = <0x10>;
			linux,phandle = <0x90>;
			phandle = <0x90>;
		};

		pwm8@0300a000 {
			compatible = "allwinner,sunxi-pwm8";
			pinctrl-names = "active", "sleep";
			reg_base = <0x300a000>;
			reg_peci_offset = <0x0>;
			reg_peci_shift = <0x8>;
			reg_peci_width = <0x1>;
			reg_pis_offset = <0x4>;
			reg_pis_shift = <0x8>;
			reg_pis_width = <0x1>;
			reg_crie_offset = <0x10>;
			reg_crie_shift = <0x10>;
			reg_crie_width = <0x1>;
			reg_cfie_offset = <0x10>;
			reg_cfie_shift = <0x11>;
			reg_cfie_width = <0x1>;
			reg_cris_offset = <0x14>;
			reg_cris_shift = <0x10>;
			reg_cris_width = <0x1>;
			reg_cfis_offset = <0x14>;
			reg_cfis_shift = <0x11>;
			reg_cfis_width = <0x1>;
			reg_clk_src_offset = <0x300>;
			reg_clk_src_shift = <0x7>;
			reg_clk_src_width = <0x2>;
			reg_bypass_offset = <0x300>;
			reg_bypass_shift = <0x5>;
			reg_bypass_width = <0x1>;
			reg_clk_gating_offset = <0x300>;
			reg_clk_gating_shift = <0x4>;
			reg_clk_gating_width = <0x1>;
			reg_clk_div_m_offset = <0x300>;
			reg_clk_div_m_shift = <0x0>;
			reg_clk_div_m_width = <0x4>;
			reg_pdzintv_offset = <0x3c>;
			reg_pdzintv_shift = <0x8>;
			reg_pdzintv_width = <0x8>;
			reg_dz_en_offset = <0x3c>;
			reg_dz_en_shift = <0x0>;
			reg_dz_en_width = <0x1>;
			reg_enable_offset = <0x40>;
			reg_enable_shift = <0x8>;
			reg_enable_width = <0x1>;
			reg_cap_en_offset = <0x44>;
			reg_cap_en_shift = <0x8>;
			reg_cap_en_width = <0x1>;
			reg_period_rdy_offset = <0x160>;
			reg_period_rdy_shift = <0xb>;
			reg_period_rdy_width = <0x1>;
			reg_pul_start_offset = <0x160>;
			reg_pul_start_shift = <0xa>;
			reg_pul_start_width = <0x1>;
			reg_mode_offset = <0x160>;
			reg_mode_shift = <0x9>;
			reg_mode_width = <0x1>;
			reg_act_sta_offset = <0x160>;
			reg_act_sta_shift = <0x8>;
			reg_act_sta_width = <0x1>;
			reg_prescal_offset = <0x160>;
			reg_prescal_shift = <0x0>;
			reg_prescal_width = <0x8>;
			reg_entire_offset = <0x164>;
			reg_entire_shift = <0x10>;
			reg_entire_width = <0x10>;
			reg_active_offset = <0x164>;
			reg_active_shift = <0x0>;
			reg_active_width = <0x10>;
			linux,phandle = <0x91>;
			phandle = <0x91>;
			device_type = "pwm8";
			pwm_used = <0x0>;
			pinctrl-0 = <0xec>;
			pinctrl-1 = <0xed>;
		};

		s_pwm@0x07020c00 {
			compatible = "allwinner,sun8iw12-s_pwm";
			reg = <0x0 0x7020c00 0x0 0x3c>;
			clocks = <0x92>;
			pwm-number = <0x1>;
			pwm-base = <0x10>;
			pwms = <0x93>;
		};

		spwm0@0x07020c00 {
			compatible = "allwinner,sunxi-pwm16";
			pinctrl-names = "active", "sleep";
			reg_base = <0x7020c00>;
			reg_busy_offset = <0x0>;
			reg_busy_shift = <0x1c>;
			reg_enable_offset = <0x0>;
			reg_enable_shift = <0x4>;
			reg_clk_gating_offset = <0x0>;
			reg_clk_gating_shift = <0x6>;
			reg_bypass_offset = <0x0>;
			reg_bypass_shift = <0x9>;
			reg_pulse_start_offset = <0x0>;
			reg_pulse_start_shift = <0x8>;
			reg_mode_offset = <0x0>;
			reg_mode_shift = <0x7>;
			reg_polarity_offset = <0x0>;
			reg_polarity_shift = <0x5>;
			reg_period_offset = <0x4>;
			reg_period_shift = <0x10>;
			reg_period_width = <0x10>;
			reg_active_offset = <0x4>;
			reg_active_shift = <0x0>;
			reg_active_width = <0x10>;
			reg_prescal_offset = <0x0>;
			reg_prescal_shift = <0x0>;
			reg_prescal_width = <0x4>;
			linux,phandle = <0x93>;
			phandle = <0x93>;
			device_type = "spwm0";
			s_pwm0_used = <0x0>;
			pinctrl-0 = <0xee>;
			pinctrl-1 = <0xef>;
		};

		boot_disp {
			compatible = "allwinner,boot_disp";
			device_type = "boot_disp";
			output_disp = <0x0>;
			output_type = <0x1>;
			output_mode = <0x4>;
		};

		ac200 {
			compatible = "allwinner,sunxi-ac200";
			pinctrl-names = "active", "sleep";
			status = "okay";
		};

		vind@0 {
			compatible = "allwinner,sunxi-vin-media", "simple-bus";
			#address-cells = <0x2>;
			#size-cells = <0x2>;
			ranges;
			device_id = <0x0>;
			vind0_clk = <0x1406f400>;
			reg = <0x0 0x6600000 0x0 0x1000>;
			clocks = <0x94 0x95 0x96 0x6 0x95 0x97 0x6 0x95 0x98 0x6 0x95 0x99 0x6 0x95 0x9a>;
			pinctrl-names = "mclk0-default", "mclk0-sleep", "mclk1-default", "mclk1-sleep", "mclk2-default", "mclk2-sleep", "mclk3-default", "mclk3-sleep";
			pinctrl-0 = <0x9b>;
			pinctrl-1 = <0x9c>;
			pinctrl-2 = <0x9d>;
			pinctrl-3 = <0x9e>;
			pinctrl-4 = <0x9f>;
			pinctrl-5 = <0xa0>;
			pinctrl-6 = <0xa1>;
			pinctrl-7 = <0xa2>;
			status = "okay";
			device_type = "vind0";

			cci@0 {
				compatible = "allwinner,sunxi-csi_cci";
				reg = <0x0 0x6614000 0x0 0x400>;
				interrupts = <0x0 0x50 0x4>;
				clocks = <0xa3>;
				device_id = <0x0>;
				status = "disabled";
				device_type = "csi_cci0";
				pinctrl-0 = <0xf0>;
			};

			cci@1 {
				compatible = "allwinner,sunxi-csi_cci";
				reg = <0x0 0x6614400 0x0 0x400>;
				interrupts = <0x0 0x51 0x4>;
				clocks = <0xa4>;
				device_id = <0x1>;
				status = "disabled";
				device_type = "csi_cci1";
				csi_cci3_used = <0x0>;
				pinctrl-0 = <0xf1>;
			};

			cci@2 {
				compatible = "allwinner,sunxi-csi_cci";
				reg = <0x0 0x6614800 0x0 0x400>;
				interrupts = <0x0 0x5a 0x4>;
				clocks = <0xa5>;
				device_id = <0x2>;
				status = "disabled";
				device_type = "csi_cci2";
				csi_cci1_used = <0x0>;
				pinctrl-0 = <0xf2>;
			};

			cci@3 {
				compatible = "allwinner,sunxi-csi_cci";
				reg = <0x0 0x6614c00 0x0 0x400>;
				interrupts = <0x0 0x5b 0x4>;
				clocks = <0xa6>;
				device_id = <0x3>;
				status = "disabled";
				device_type = "csi_cci3";
				pinctrl-0 = <0xf3>;
			};

			csi@0 {
				device_type = "csi0";
				compatible = "allwinner,sunxi-csi";
				reg = <0x0 0x6601000 0x0 0x1000>;
				interrupts = <0x0 0x4e 0x4>;
				device_id = <0x0>;
				status = "okay";
			};

			csi@1 {
				device_type = "csi1";
				compatible = "allwinner,sunxi-csi";
				reg = <0x0 0x6602000 0x0 0x1000>;
				interrupts = <0x0 0x4f 0x4>;
				device_id = <0x1>;
				status = "okay";
			};

			csi@2 {
				device_type = "csi2";
				compatible = "allwinner,sunxi-csi";
				reg = <0x0 0x6603000 0x0 0x1000>;
				interrupts = <0x0 0x58 0x4>;
				pinctrl-names = "default", "sleep";
				pinctrl-1 = <0xa8>;
				device_id = <0x2>;
				status = "disabled";
				pinctrl-0 = <0xf4>;
			};

			csi@3 {
				device_type = "csi3";
				compatible = "allwinner,sunxi-csi";
				reg = <0x0 0x6604000 0x0 0x1000>;
				interrupts = <0x0 0x59 0x4>;
				pinctrl-names = "default", "sleep";
				pinctrl-1 = <0xaa>;
				device_id = <0x3>;
				status = "disabled";
				pinctrl-0 = <0xf5>;
			};

			mipi@0 {
				compatible = "allwinner,sunxi-mipi";
				reg = <0x0 0x660c000 0x0 0x1000>;
				interrupts = <0x0 0x52 0x4>;
				device_id = <0x0>;
				status = "okay";
			};

			mipi@1 {
				compatible = "allwinner,sunxi-mipi";
				reg = <0x0 0x660e000 0x0 0x1000>;
				interrupts = <0x0 0x53 0x4>;
				device_id = <0x1>;
				status = "okay";
			};

			isp@0 {
				compatible = "allwinner,sunxi-isp";
				reg = <0x0 0x2100000 0x0 0x800>;
				interrupts = <0x0 0x21 0x4>;
				device_id = <0x0>;
				status = "okay";
			};

			isp@1 {
				compatible = "allwinner,sunxi-isp";
				reg = <0x0 0x2100800 0x0 0x800>;
				interrupts = <0x0 0x22 0x4>;
				device_id = <0x1>;
				status = "okay";
			};

			isp@2 {
				compatible = "allwinner,sunxi-isp";
				device_id = <0x2>;
				status = "okay";
			};

			isp@3 {
				compatible = "allwinner,sunxi-isp";
				device_id = <0x3>;
				status = "okay";
			};

			scaler@0 {
				compatible = "allwinner,sunxi-scaler";
				reg = <0x0 0x2101000 0x0 0x400>;
				device_id = <0x0>;
				status = "okay";
			};

			scaler@1 {
				compatible = "allwinner,sunxi-scaler";
				reg = <0x0 0x2101400 0x0 0x400>;
				device_id = <0x1>;
				status = "okay";
			};

			scaler@2 {
				compatible = "allwinner,sunxi-scaler";
				reg = <0x0 0x2101800 0x0 0x400>;
				device_id = <0x2>;
				status = "okay";
			};

			scaler@3 {
				compatible = "allwinner,sunxi-scaler";
				reg = <0x0 0x2101c00 0x0 0x400>;
				device_id = <0x3>;
				status = "okay";
			};

			scaler@4 {
				compatible = "allwinner,sunxi-scaler";
				reg = <0x0 0x2102000 0x0 0x400>;
				device_id = <0x4>;
				status = "okay";
			};

			scaler@5 {
				compatible = "allwinner,sunxi-scaler";
				reg = <0x0 0x2102400 0x0 0x400>;
				device_id = <0x5>;
				status = "okay";
			};

			scaler@6 {
				compatible = "allwinner,sunxi-scaler";
				reg = <0x0 0x2102800 0x0 0x400>;
				device_id = <0x6>;
				status = "okay";
			};

			scaler@7 {
				compatible = "allwinner,sunxi-scaler";
				reg = <0x0 0x2102c00 0x0 0x400>;
				device_id = <0x7>;
				status = "okay";
			};

			actuator@0 {
				device_type = "actuator0";
				compatible = "allwinner,sunxi-actuator";
				actuator0_name = "ad5820_act";
				actuator0_slave = <0x18>;
				actuator0_afvdd = "afvcc-csi";
				actuator0_afvdd_vol = <0x2ab980>;
				status = "disabled";
				linux,phandle = <0xac>;
				phandle = <0xac>;
				actuator0_af_pwdn;
			};

			flash@0 {
				device_type = "flash0";
				compatible = "allwinner,sunxi-flash";
				flash0_type = <0x2>;
				device_id = <0x0>;
				status = "disabled";
				linux,phandle = <0xab>;
				phandle = <0xab>;
				flash0_en;
				flash0_mode;
				flash0_flvdd;
				flash0_flvdd_vol;
			};

			sensor@0 {
				device_type = "sensor0";
				sensor0_mname = "lt6911_mipi";
				sensor0_twi_cci_spi = <0x0>;
				sensor0_twi_cci_id = <0x2>;
				sensor0_twi_addr = <0x56>;
				sensor0_mclk_id = <0x2>;
				sensor0_pos = "front";
				sensor0_isp_used = <0x0>;
				sensor0_fmt = <0x0>;
				sensor0_vflip = <0x0>;
				sensor0_hflip = <0x0>;
				sensor0_iovdd = "iovdd-csi";
				sensor0_iovdd_vol = <0x325aa0>;
				sensor0_avdd = "avdd-csi";
				sensor0_avdd_vol = <0x2ab980>;
				sensor0_dvdd_vol = <0x124f80>;
				flash_handle = <0xab>;
				act_handle = <0xac>;
				status = "okay";
				sensor0_stby_mode = <0x0>;
				sensor0_dvdd;
				sensor0_power_en;
				sensor0_reset = <0x4f 0x8 0xc 0x1 0x0 0x1 0x0>;
				sensor0_pwdn = <0x4f 0x8 0xe 0x1 0x0 0x1 0x0>;
			};

			sensor@1 {
				device_type = "sensor1";
				sensor1_mname = "imx317_mipi_2";
				sensor1_twi_cci_spi = <0x0>;
				sensor1_twi_cci_id = <0x3>;
				sensor1_twi_addr = <0x34>;
				sensor1_mclk_id = <0x3>;
				sensor1_pos = "rear";
				sensor1_isp_used = <0x1>;
				sensor1_fmt = <0x1>;
				sensor1_vflip = <0x1>;
				sensor1_hflip = <0x1>;
				sensor1_iovdd = "iovdd-csi";
				sensor1_iovdd_vol = <0x1b7740>;
				sensor1_avdd = "avdd-csi";
				sensor1_avdd_vol = <0x2ab980>;
				sensor1_dvdd_vol = <0x124f80>;
				flash_handle;
				act_handle;
				status = "disabled";
				sensor1_stby_mode = <0x0>;
				sensor1_dvdd;
				sensor1_power_en;
				sensor1_reset = <0x4f 0x8 0xd 0x1 0x0 0x1 0x0>;
				sensor1_pwdn = <0x4f 0x8 0xf 0x1 0x0 0x1 0x0>;
			};

			vinc@0 {
				device_type = "vinc0";
				compatible = "allwinner,sunxi-vin-core";
				reg = <0x0 0x6609000 0x0 0x200>;
				interrupts = <0x0 0x4a 0x4>;
				vinc0_csi_sel = <0x0>;
				vinc0_mipi_sel = <0x0>;
				vinc0_isp_sel = <0x0>;
				vinc0_rear_sensor_sel = <0x0>;
				vinc0_front_sensor_sel = <0x0>;
				vinc0_sensor_list = <0x0>;
				device_id = <0x0>;
				status = "okay";
				vinc0_isp_tx_ch = <0x0>;
			};

			vinc@1 {
				device_type = "vinc1";
				compatible = "allwinner,sunxi-vin-core";
				reg = <0x0 0x6609200 0x0 0x200>;
				interrupts = <0x0 0x4b 0x4>;
				vinc1_csi_sel = <0x1>;
				vinc1_mipi_sel = <0x1>;
				vinc1_isp_sel = <0x0>;
				vinc1_rear_sensor_sel = <0x0>;
				vinc1_front_sensor_sel = <0x0>;
				vinc1_sensor_list = <0x0>;
				device_id = <0x1>;
				status = "disabled";
				vinc1_isp_tx_ch = <0x0>;
			};

			vinc@2 {
				device_type = "vinc2";
				compatible = "allwinner,sunxi-vin-core";
				reg = <0x0 0x6609400 0x0 0x200>;
				interrupts = <0x0 0x4c 0x4>;
				vinc2_csi_sel = <0x0>;
				vinc2_mipi_sel = <0x0>;
				vinc2_isp_sel = <0x0>;
				vinc2_rear_sensor_sel = <0x0>;
				vinc2_front_sensor_sel = <0x0>;
				vinc2_sensor_list = <0x0>;
				device_id = <0x2>;
				status = "disabled";
				vinc2_isp_tx_ch = <0x0>;
			};

			vinc@3 {
				device_type = "vinc3";
				compatible = "allwinner,sunxi-vin-core";
				reg = <0x0 0x6609600 0x0 0x200>;
				interrupts = <0x0 0x4d 0x4>;
				vinc3_csi_sel = <0x1>;
				vinc3_mipi_sel = <0x1>;
				vinc3_isp_sel = <0x0>;
				vinc3_rear_sensor_sel = <0x0>;
				vinc3_front_sensor_sel = <0x0>;
				vinc3_sensor_list = <0x0>;
				device_id = <0x3>;
				status = "disabled";
				vinc3_isp_tx_ch = <0x0>;
			};

			vinc@4 {
				device_type = "vinc4";
				compatible = "allwinner,sunxi-vin-core";
				reg = <0x0 0x6609800 0x0 0x200>;
				interrupts = <0x0 0x54 0x4>;
				vinc4_csi_sel = <0x2>;
				vinc4_mipi_sel = <0xff>;
				vinc4_isp_sel = <0x1>;
				vinc4_rear_sensor_sel = <0x0>;
				vinc4_front_sensor_sel = <0x0>;
				vinc4_sensor_list = <0x0>;
				device_id = <0x4>;
				status = "disabled";
				vinc4_isp_tx_ch = <0x0>;
			};

			vinc@5 {
				device_type = "vinc5";
				compatible = "allwinner,sunxi-vin-core";
				reg = <0x0 0x6609a00 0x0 0x200>;
				interrupts = <0x0 0x55 0x4>;
				vinc5_csi_sel = <0x2>;
				vinc5_mipi_sel = <0xff>;
				vinc5_isp_sel = <0x1>;
				vinc5_rear_sensor_sel = <0x0>;
				vinc5_front_sensor_sel = <0x0>;
				vinc5_sensor_list = <0x0>;
				device_id = <0x5>;
				status = "disabled";
				vinc5_isp_tx_ch = <0x0>;
			};

			vinc@6 {
				device_type = "vinc6";
				compatible = "allwinner,sunxi-vin-core";
				reg = <0x0 0x6609c00 0x0 0x200>;
				interrupts = <0x0 0x56 0x4>;
				vinc6_csi_sel = <0x2>;
				vinc6_mipi_sel = <0xff>;
				vinc6_isp_sel = <0x1>;
				vinc6_rear_sensor_sel = <0x0>;
				vinc6_front_sensor_sel = <0x0>;
				vinc6_sensor_list = <0x0>;
				device_id = <0x6>;
				status = "disabled";
				vinc6_isp_tx_ch = <0x0>;
			};

			vinc@7 {
				device_type = "vinc7";
				compatible = "allwinner,sunxi-vin-core";
				reg = <0x0 0x6609e00 0x0 0x200>;
				interrupts = <0x0 0x57 0x4>;
				vinc7_csi_sel = <0x2>;
				vinc7_mipi_sel = <0xff>;
				vinc7_isp_sel = <0x1>;
				vinc7_rear_sensor_sel = <0x0>;
				vinc7_front_sensor_sel = <0x0>;
				vinc7_sensor_list = <0x0>;
				device_id = <0x7>;
				status = "disabled";
				vinc7_isp_tx_ch = <0x0>;
			};
		};

		vdevice@0 {
			compatible = "allwinner,sun8i-vdevice";
			device_type = "Vdevice";
			pinctrl-names = "default";
			test-gpios = <0x4f 0x1 0x0 0x1 0x2 0x2 0x1>;
			status = "disabled";
			pinctrl-0 = <0xfc>;
		};

		ce@1904000 {
			compatible = "allwinner,sunxi-ce";
			device_name = "ce";
			reg = <0x0 0x1904000 0x0 0xa0 0x0 0x1904800 0x0 0xa0>;
			interrupts = <0x0 0x23 0xff01 0x0 0x24 0xff01>;
			clock-frequency = <0x11e1a300>;
			clocks = <0xae 0x70>;
		};

		deinterlace@0x01420000 {
			#address-cells = <0x1>;
			#size-cells = <0x0>;
			compatible = "allwinner,sunxi-deinterlace";
			reg = <0x0 0x1420000 0x0 0x20c>;
			interrupts = <0x0 0x20 0x4>;
			clocks = <0xaf 0x2>;
			status = "okay";
		};

		pmu@0 {
			interrupts = <0x0 0x68 0x4>;
			status = "okay";
			device_type = "pmu0";
			compatible = "axp233";
			pmu_id = <0x5>;
			pmu_vbusen_func = <0x0>;
			pmu_reset = <0x0>;
			pmu_irq_wakeup = <0x1>;
			pmu_hot_shutdown = <0x1>;
			pmu_inshort = <0x0>;

			powerkey@0 {
				status = "okay";
				device_type = "powerkey0";
				compatible = "axp233-powerkey";
				pmu_powkey_off_time = <0x1770>;
				pmu_powkey_off_func = <0x0>;
				pmu_powkey_off_en = <0x1>;
				pmu_powkey_long_time = <0x5dc>;
				pmu_powkey_on_time = <0x3e8>;
			};

			regulator@0 {
				status = "okay";
				device_type = "regulator0";
				compatible = "axp233-regulator";
				regulator_count = <0x13>;
				regulator1 = "axp233_dcdc1 none vcc-3v3 vcc-io vcc33-usb vcc33-pc vcc-pd vcc-pa vcc-card vcc-nand vcc-ephy audio-33";
				regulator2 = "axp233_dcdc2 none vdd-cpua";
				regulator3 = "axp233_dcdc3 none vdd-sys vdd09-usb";
				regulator4 = "axp233_dcdc4 none vcc18-pc vcc-lvds vcc18-lcd vcc18-dsi vcc18-hdmi vcc18-cmbcsi0 vcc18-cmbcsi1 vcc-efuse";
				regulator5 = "axp233_dcdc5 none vcc-dram";
				regulator6 = "axp233_rtc none vcc-rtc";
				regulator7 = "axp233_aldo1 none avdd-csi";
				regulator8 = "axp233_aldo2 none";
				regulator9 = "axp233_aldo3 none vdd18-lpddr vdd18-dram vcc-pll avcc";
				regulator10 = "axp233_dldo1 none vcc-sec";
				regulator11 = "axp233_dldo2 none vdd09-hdmi";
				regulator12 = "axp233_eldo1 none vcc-pg vcc18-wifi vcc-dcxo-io";
				regulator13 = "axp233_eldo2 none vcc-pf";
				regulator14 = "axp233_eldo3 none vcc-pl";
				regulator15 = "axp233_ldoio0 none vcc-tv";
				regulator16 = "axp233_ldoio1 none vcc-pi iovdd-csi iovcc-csi";
				regulator17 = "axp233_swout none vcc33-wifi";
				regulator18 = "axp233_dc1sw none vcc-lcd vcc-ctp";
				regulator19 = "axp233_dc5ldo none vdd-cpus";
			};

			axp_gpio@0 {
				gpio-controller;
				#size-cells = <0x0>;
				#gpio-cells = <0x6>;
				status = "okay";
				linux,phandle = <0xe3>;
				phandle = <0xe3>;
				device_type = "axp_gpio0";
				compatible = "axp233-gpio";
			};

			charger@0 {
				status = "okay";
				device_type = "charger0";
				compatible = "axp233-charger";
				pmu_bat_unused = <0x0>;
				pmu_chg_ic_temp = <0x0>;
				pmu_battery_rdc = <0xf0>;
				pmu_battery_cap = <0x3e0>;
				pmu_runtime_chgcur = <0x1c2>;
				pmu_suspend_chgcur = <0x5dc>;
				pmu_shutdown_chgcur = <0x5dc>;
				pmu_init_chgvol = <0x1068>;
				pmu_ac_vol = <0xfa0>;
				pmu_ac_cur = <0x0>;
				pmu_usbpc_vol = <0x1130>;
				pmu_usbpc_cur = <0x0>;
				pmu_battery_warning_level1 = <0xf>;
				pmu_battery_warning_level2 = <0x0>;
				pmu_chgled_func = <0x1>;
				pmu_chgled_type = <0x0>;
				power_start = <0x1>;
				pmu_ocv_en = <0x1>;
				pmu_cou_en = <0x1>;
				pmu_update_min_time = <0x1e>;
				pmu_safe_vol = <0xdf2>;
				pmu_bat_para1 = <0x0>;
				pmu_bat_para2 = <0x0>;
				pmu_bat_para3 = <0x0>;
				pmu_bat_para4 = <0x0>;
				pmu_bat_para5 = <0x0>;
				pmu_bat_para6 = <0x0>;
				pmu_bat_para7 = <0x0>;
				pmu_bat_para8 = <0x0>;
				pmu_bat_para9 = <0x1>;
				pmu_bat_para10 = <0x2>;
				pmu_bat_para11 = <0x3>;
				pmu_bat_para12 = <0x5>;
				pmu_bat_para13 = <0x8>;
				pmu_bat_para14 = <0xe>;
				pmu_bat_para15 = <0x19>;
				pmu_bat_para16 = <0x26>;
				pmu_bat_para17 = <0x2c>;
				pmu_bat_para18 = <0x31>;
				pmu_bat_para19 = <0x35>;
				pmu_bat_para20 = <0x39>;
				pmu_bat_para21 = <0x3d>;
				pmu_bat_para22 = <0x40>;
				pmu_bat_para23 = <0x45>;
				pmu_bat_para24 = <0x4b>;
				pmu_bat_para25 = <0x4f>;
				pmu_bat_para26 = <0x53>;
				pmu_bat_para27 = <0x57>;
				pmu_bat_para28 = <0x5c>;
				pmu_bat_para29 = <0x5d>;
				pmu_bat_para30 = <0x60>;
				pmu_bat_para31 = <0x62>;
				pmu_bat_para32 = <0x64>;
				pmu_bat_temp_enable = <0x0>;
				pmu_bat_charge_ltf = <0x8d5>;
				pmu_bat_charge_htf = <0x184>;
				pmu_bat_shutdown_ltf = <0xc80>;
				pmu_bat_shutdown_htf = <0xed>;
				pmu_bat_temp_para1 = <0x1d2a>;
				pmu_bat_temp_para2 = <0x1180>;
				pmu_bat_temp_para3 = <0xdbe>;
				pmu_bat_temp_para4 = <0xae2>;
				pmu_bat_temp_para5 = <0x8af>;
				pmu_bat_temp_para6 = <0x6fc>;
				pmu_bat_temp_para7 = <0x5a8>;
				pmu_bat_temp_para8 = <0x3c9>;
				pmu_bat_temp_para9 = <0x298>;
				pmu_bat_temp_para10 = <0x1d2>;
				pmu_bat_temp_para11 = <0x189>;
				pmu_bat_temp_para12 = <0x14d>;
				pmu_bat_temp_para13 = <0x11b>;
				pmu_bat_temp_para14 = <0xf2>;
				pmu_bat_temp_para15 = <0xb3>;
				pmu_bat_temp_para16 = <0x86>;
			};
		};

		nmi@0x01f00c00 {
			#address-cells = <0x1>;
			#size-cells = <0x0>;
			compatible = "allwinner,sunxi-nmi";
			reg = <0x0 0x1f00c00 0x0 0x50>;
			nmi_irq_ctrl = <0xc>;
			nmi_irq_en = <0x40>;
			nmi_irq_status = <0x10>;
			nmi_irq_mask = <0x50>;
			status = "okay";
		};

		nand0@04011000 {
			compatible = "allwinner,sun8iw12-nand";
			device_type = "nand0";
			reg = <0x0 0x4011000 0x0 0x1000>;
			interrupts = <0x0 0x1d 0x4>;
			clocks = <0xb0 0xb1 0xb2>;
			pinctrl-names = "default", "sleep";
			pinctrl-1 = <0xb5>;
			nand0_regulator1 = "vcc-nand";
			nand0_regulator2 = "none";
			nand0_cache_level = <0x55aaaa55>;
			nand0_flush_cache_num = <0x55aaaa55>;
			nand0_capacity_level = <0x55aaaa55>;
			nand0_id_number_ctl = <0x55aaaa55>;
			nand0_print_level = <0x55aaaa55>;
			nand0_p0 = <0x55aaaa55>;
			nand0_p1 = <0x55aaaa55>;
			nand0_p2 = <0x55aaaa55>;
			nand0_p3 = <0x55aaaa55>;
			status = "disabled";
			nand_support_2ch = <0x0>;
			pinctrl-0 = <0xe4 0xe5>;
		};

		spinand@05010000 {
			compatible = "allwinner,sunxi-spinand";
			device_type = "spinand";
			reg = <0x0 0x5010000 0x0 0x1000>;
			interrupts = <0x0 0x36 0x4>;
			clocks = <0x2 0x60>;
			pinctrl-names = "default", "sleep";
			pinctrl-0 = <0xdb 0xdc>;
			pinctrl-1 = <0x63>;
			nand0_regulator1 = "vcc-nand";
			nand0_regulator2 = "none";
			nand0_cache_level = <0x55aaaa55>;
			nand0_flush_cache_num = <0x55aaaa55>;
			nand0_capacity_level = <0x55aaaa55>;
			nand0_id_number_ctl = <0x55aaaa55>;
			nand0_print_level = <0x55aaaa55>;
			nand0_p0 = <0x55aaaa55>;
			nand0_p1 = <0x55aaaa55>;
			nand0_p2 = <0x55aaaa55>;
			nand0_p3 = <0x55aaaa55>;
			status = "disabled";
		};

		thermal_sensor {
			compatible = "allwinner,thermal_sensor";
			reg = <0x0 0x5070400 0x0 0x400>;
			interrupts = <0x0 0x1 0x0>;
			clocks = <0x6 0xb6>;
			sensor_num = <0x3>;
			combine_num = <0x2>;
			shut_temp = <0x6e>;
			status = "okay";

			ths_combine0 {
				compatible = "allwinner,ths_combine0";
				#thermal-sensor-cells = <0x1>;
				combine_sensor_num = <0x1>;
				combine_sensor_type = "CPU";
				combine_sensor_temp_type = "max";
				combine_sensor_id = <0x0>;
				linux,phandle = <0xb7>;
				phandle = <0xb7>;
			};

			ths_combine1 {
				compatible = "allwinner,ths_combine1";
				#thermal-sensor-cells = <0x1>;
				combine_sensor_num = <0x2>;
				combine_sensor_type = "VE&ISP";
				combine_sensor_temp_type = "max";
				combine_sensor_id = <0x1 0x2>;
				linux,phandle = <0xbe>;
				phandle = <0xbe>;
			};
		};

		cpu_budget_cool {
			compatible = "allwinner,budget_cooling";
			#cooling-cells = <0x2>;
			status = "okay";
			state_cnt = <0x6>;
			cluster_num = <0x1>;
			state0 = <0x171240 0x4>;
			state1 = <0x159b40 0x4>;
			state2 = <0x124f80 0x4>;
			state3 = <0xf6180 0x3>;
			state4 = <0xf6180 0x2>;
			state5 = <0xf6180 0x1>;
			linux,phandle = <0xb9>;
			phandle = <0xb9>;
		};

		thermal-zones {

			cpu_thermal_zone {
				polling-delay-passive = <0x3e8>;
				polling-delay = <0x2710>;
				thermal-sensors = <0xb7 0x0>;

				trips {

					t0 {
						temperature = <0x41>;
						type = "passive";
						hysteresis = <0x0>;
						linux,phandle = <0xb8>;
						phandle = <0xb8>;
					};

					t1 {
						temperature = <0x4b>;
						type = "passive";
						hysteresis = <0x0>;
						linux,phandle = <0xba>;
						phandle = <0xba>;
					};

					t2 {
						temperature = <0x55>;
						type = "passive";
						hysteresis = <0x0>;
						linux,phandle = <0xbb>;
						phandle = <0xbb>;
					};

					t3 {
						temperature = <0x5f>;
						type = "passive";
						hysteresis = <0x0>;
						linux,phandle = <0xbc>;
						phandle = <0xbc>;
					};

					t4 {
						temperature = <0x69>;
						type = "passive";
						hysteresis = <0x0>;
						linux,phandle = <0xbd>;
						phandle = <0xbd>;
					};

					t5 {
						temperature = <0x6e>;
						type = "critical";
						hysteresis = <0x0>;
					};
				};

				cooling-maps {

					bind0 {
						contribution = <0x0>;
						trip = <0xb8>;
						cooling-device = <0xb9 0x1 0x1>;
					};

					bind1 {
						contribution = <0x0>;
						trip = <0xba>;
						cooling-device = <0xb9 0x2 0x2>;
					};

					bind2 {
						contribution = <0x0>;
						trip = <0xbb>;
						cooling-device = <0xb9 0x3 0x3>;
					};

					bind3 {
						contribution = <0x0>;
						trip = <0xbc>;
						cooling-device = <0xb9 0x4 0x4>;
					};

					bind4 {
						contribution = <0x0>;
						trip = <0xbd>;
						cooling-device = <0xb9 0x5 0x5>;
					};
				};
			};

			ve_isp_thermal_zone {
				polling-delay-passive = <0x3e8>;
				polling-delay = <0x2710>;
				thermal-sensors = <0xbe 0x1>;

				trips {

					t3 {
						temperature = <0x6e>;
						type = "critical";
						hysteresis = <0x0>;
					};
				};
			};
		};

		gpadc {
			compatible = "allwinner,sunxi-gpadc";
			reg = <0x0 0x5070000 0x0 0x400>;
			interrupts = <0x0 0x0 0x0>;
			clocks = <0xbf>;
			key_cnt = <0x5>;
			key0 = <0x73 0x73>;
			key1 = <0xeb 0x72>;
			key2 = <0x168 0x8b>;
			key3 = <0x1e0 0x1c>;
			key4 = <0x24e 0x66>;
			status = "okay";
			device_type = "gpadc";
			channel_num = <0x4>;
			channel_select = <0x1>;
			channel_data_select = <0x0>;
			channel_compare_select = <0x1>;
			channel_cld_select = <0x1>;
			channel_chd_select = <0x4>;
			channel0_compare_lowdata = <0x19f0a0>;
			channel0_compare_higdata = <0x124f80>;
			channel1_compare_lowdata = <0x704e0>;
			channel1_compare_higdata = <0x124f80>;
			channel2_compare_lowdata = <0x704e0>;
			channel2_compare_higdata = <0x30d40>;
			channel3_compare_lowdata = <0x704e0>;
			channel3_compare_higdata = <0x124f80>;
		};

		eth@05020000 {
			compatible = "allwinner,sunxi-gmac";
			reg = <0x0 0x5020000 0x0 0xffff 0x0 0x3000030 0x0 0x4>;
			interrupts = <0x0 0x1b 0x4>;
			interrupt-names = "gmacirq";
			clocks = <0xc0 0xc1>;
			clock-names = "gmac", "ephy";
			pinctrl-names = "default", "sleep";
			pinctrl-1 = <0xc3>;
			phy-mode = "rgmii";
			tx-delay = <0x7>;
			rx-delay = <0x1f>;
			gmac-power0 = "vcc-ephy";
			status = "okay";
			device_type = "gmac0";
			pinctrl-0 = <0xcf>;
			phy-rst = <0x4f 0x1 0x3 0x1 0xffffffff 0xffffffff 0x0>;
			gmac-power1;
			gmac-power2;
			use_ephy25m = <0x1>;
		};

		cpucfg@09010000 {
			compatible = "allwinner,sunxi-cpucfg";
			reg = <0x0 0x9010000 0x0 0xc8>;
		};

		cpuscfg@07000400 {
			compatible = "allwinner,sunxi-cpuscfg";
			reg = <0x0 0x7000400 0x0 0x400>;
		};

		sysctl@03000000 {
			compatible = "allwinner,sunxi-sysctl";
			reg = <0x0 0x3000000 0x0 0x1000>;
		};

		product {
			device_type = "product";
			version = "100";
			machine = "v5s_hdmi";
		};

		platform {
			device_type = "platform";
			eraseflag = <0x0>;
		};

		target {
			device_type = "target";
			boot_clock = <0x3f0>;
			storage_type = <0xffffffff>;
		};

		norflash {
			device_type = "norflash";
			size = <0x20>;
		};

		auto_update_key {
			device_type = "auto_update_key";
		};

		power_sply {
			device_type = "power_sply";
			dcdc1_vol = <0xf4f24>;
			dcdc2_vol = <0xf45c4>;
			dcdc3_vol = <0xf45ec>;
			dldo1_vol = <0xce4>;
			dldo2_vol = <0x384>;
			eldo1_vol = <0xf4948>;
			eldo2_vol = <0xf4f24>;
			eldo3_vol = <0xf4948>;
			dc1sw_vol = <0xf4f24>;
		};

		card_boot {
			device_type = "card_boot";
			logical_start = <0xa000>;
			sprite_gpio0;
		};

		pm_para {
			device_type = "pm_para";
			standby_mode = <0x1>;
		};

		card0_boot_para {
			device_type = "card0_boot_para";
			card_ctrl = <0x0>;
			card_high_speed = <0x1>;
			card_line = <0x4>;
			pinctrl-0 = <0xca>;
		};

		card2_boot_para {
			device_type = "card2_boot_para";
			card_ctrl = <0x2>;
			card_high_speed = <0x1>;
			card_line = <0x8>;
			pinctrl-0 = <0xcb>;
			sdc_ex_dly_used = <0x2>;
		};

		twi_para {
			device_type = "twi_para";
			twi_port = <0x0>;
			pinctrl-0 = <0xcc>;
		};

		uart_para {
			device_type = "uart_para";
			uart_debug_port = <0x0>;
			pinctrl-0 = <0xcd>;
		};

		jtag_para {
			device_type = "jtag_para";
			jtag_enable = <0x0>;
			pinctrl-0 = <0xce>;
		};

		clock {
			device_type = "clock";
			pll4 = <0x12c>;
			pll6 = <0x258>;
			pll8 = <0x168>;
			pll9 = <0x129>;
			pll10 = <0x108>;
		};

		ctp {
			device_type = "ctp";
			compatible = "allwinner,sunxi-ctp-para";
			status = "disabled";
			ctp_name = "gt9xx_ts";
			ctp_twi_id = <0x0>;
			ctp_twi_addr = <0x5d>;
			ctp_screen_max_x = <0x1e0>;
			ctp_screen_max_y = <0x356>;
			ctp_revert_x_flag = <0x1>;
			ctp_revert_y_flag = <0x0>;
			ctp_exchange_x_y_flag = <0x1>;
			ctp_int_port = <0x4f 0x7 0x4 0x6 0xffffffff 0xffffffff 0xffffffff>;
			ctp_wakeup = <0x4f 0x7 0x8 0x1 0xffffffff 0xffffffff 0x1>;
			ctp_power_ldo = "vcc-ctp";
			ctp_power_ldo_vol = <0xce4>;
			ctp_power_io;
		};

		ft6x_ts {
			device_type = "ft6x_ts";
			status = "disabled";
			compatible = "focaltech,focaltech_ts";
			i2c_id = <0x0>;
			ctp_screen_max_x = <0x438>;
			ctp_screen_max_y = <0x50a>;
			ctp_exchange_x_y_flag = <0x0>;
			ctp_revert_x_flag = <0x0>;
			ctp_revert_y_flag = <0x0>;
			ctp-int-gpio = <0x4f 0x1 0x0 0x1 0xffffffff 0xffffffff 0xffffffff>;
			ctp-rst-gpio = <0x4f 0x1 0x1 0x1 0xffffffff 0xffffffff 0x1>;
		};

		motor_para {
			device_type = "motor_para";
			motor_used = <0x0>;
			motor_shake = <0xe3 0xfffe 0x3 0x1 0xffffffff 0xffffffff 0x1>;
		};

		tvout_para {
			device_type = "tvout_para";
			tvout_used;
			tvout_channel_num;
			tv_en;
		};

		tvin_para {
			device_type = "tvin_para";
			tvin_used;
			tvin_channel_num;
		};

		smc_para {
			device_type = "smc_para";
			smc_used;
			smc_rst;
			smc_vppen;
			smc_vppp;
			smc_det;
			smc_vccen;
			smc_sck;
			smc_sda;
		};

		gsensor {
			device_type = "gsensor";
			status = "disabled";
			gsensor_twi_id = <0x1>;
			gsensor_twi_addr = <0x27>;
			gsensor_vcc_io = "vcc-3v3";
			gsensor_vcc_io_val = <0xce4>;
			gsensor_int1 = <0xc9 0xb 0xd 0x6 0x1 0xffffffff 0xffffffff>;
			gsensor_int2;
		};

		gps_para {
			device_type = "gps_para";
		};

		ir_cut {
			device_type = "ir_cut";
			compatible = "allwinner,ir_cut";
			status = "disabled";
			ir_cut_num = <0x2>;
			ir_cut_gpio0 = <0x4f 0x7 0x4 0x1 0xffffffff 0xffffffff 0x0>;
			ir_cut_gpio1 = <0x4f 0x7 0x8 0x1 0xffffffff 0xffffffff 0x0>;
		};

		dvfs_table {
			device_type = "dvfs_table";
			L_max_freq = <0x3c14dc00>;
			L_min_freq = <0x7270e00>;
			L_LV_count = <0x8>;
			L_LV1_freq = <0x41cdb400>;
			L_LV1_volt = <0x514>;
			L_LV2_freq = <0x3ef14800>;
			L_LV2_volt = <0x4ec>;
			L_LV3_freq = <0x337f9800>;
			L_LV3_volt = <0x4b0>;
			L_LV4_freq = <0x2aea5400>;
			L_LV4_volt = <0x44c>;
			L_LV5_freq = <0x1c9c3800>;
			L_LV5_volt = <0x3e8>;
			L_LV6_freq = <0x0>;
			L_LV6_volt = <0x3e8>;
			L_LV7_freq = <0x0>;
			L_LV7_volt = <0x3e8>;
			L_LV8_freq = <0x0>;
			L_LV8_volt = <0x3e8>;
			B_max_freq = <0x3c14dc00>;
			B_min_freq = <0x7270e00>;
			B_LV_count = <0x8>;
			B_LV1_freq = <0x41cdb400>;
			B_LV1_volt = <0x514>;
			B_LV2_freq = <0x3ef14800>;
			B_LV2_volt = <0x4ec>;
			B_LV3_freq = <0x337f9800>;
			B_LV3_volt = <0x4b0>;
			B_LV4_freq = <0x2aea5400>;
			B_LV4_volt = <0x44c>;
			B_LV5_freq = <0x1c9c3800>;
			B_LV5_volt = <0x3e8>;
			B_LV6_freq = <0x0>;
			B_LV6_volt = <0x3e8>;
			B_LV7_freq = <0x0>;
			B_LV7_volt = <0x3e8>;
			B_LV8_freq = <0x0>;
			B_LV8_volt = <0x3e8>;
		};

		s_rsb0 {
			device_type = "s_rsb0";
			s_rsb_used = <0x0>;
			pinctrl-0 = <0xfa>;
		};

		gpioled {
			device_type = "gpioled";
			compatible = "gpio-leds";

			work {
				device_type = "work";
				label = "rec_led";
				gpios = <0x4f 0x1 0x7 0x1 0xffffffff 0xffffffff 0x0>;
				linux,default-trigger = "heartbeat";
				default-state = "on";
			};

			wifi {
				device_type = "wifi";
				label = "wifi_led";
				gpios = <0x4f 0x1 0x6 0x1 0xffffffff 0xffffffff 0x1>;
				linux,default-trigger = "oneshot";
				default-state = "on";
			};
		};

		gpio_para {
			device_type = "gpio_para";
			compatible = "allwinner,sunxi-init-gpio";
			status = "disabled";
			gpio_num = <0x1>;
			gpio_pin_1 = <0x4f 0x1 0x1 0x1 0x3 0x3 0x1>;
		};

		gpio_bias {
			device_type = "gpio_bias";
			pa_bias = "axp809:dcdc1:3300";
			pd_bias = "axp809:bldo1:3300";
			pe_bias = "axp809:dldo1:2800";
			pf_bias = "axp809:eldo2:3300";
			pg_bias = "axp809:eldo1:1800";
			pi_bias = "axp809:dldo1:1800";
			pj_bias = "axp809:dcdce:2800";
			vcc_bias = "axp809:dcdc1:3300";
		};
	};

	aliases {
		serial0 = "/soc@03000000/uart@05000000", "/soc@03000000/uart@05000000";
		serial1 = "/soc@03000000/uart@05000400", "/soc@03000000/uart@05000400";
		serial2 = "/soc@03000000/uart@05000800", "/soc@03000000/uart@05000800";
		serial3 = "/soc@03000000/uart@05000c00", "/soc@03000000/uart@05000c00";
		serial4 = "/soc@03000000/uart@05001000", "/soc@03000000/uart@05001000";
		twi0 = "/soc@03000000/twi@0x05002000", "/soc@03000000/twi@0x05002000";
		twi1 = "/soc@03000000/twi@0x05002400", "/soc@03000000/twi@0x05002400";
		twi2 = "/soc@03000000/twi@0x05002800", "/soc@03000000/twi@0x05002800";
		twi3 = "/soc@03000000/twi@0x05002c00", "/soc@03000000/twi@0x05002c00";
		spi0 = "/soc@03000000/spi@05010000", "/soc@03000000/spi@05010000";
		spi1 = "/soc@03000000/spi@05011000", "/soc@03000000/spi@05011000";
		spi2 = "/soc@03000000/spi@05012000", "/soc@03000000/spi@05012000";
		spi3 = "/soc@03000000/spi@05013000", "/soc@03000000/spi@05013000";
		gmac0 = "/soc@03000000/eth@05020000", "/soc@03000000/eth@05020000";
		global_timer0 = "/soc@03000000/timer@03009000", "/soc@03000000/timer@03009000";
		mmc0 = "/soc@03000000/sdmmc@04020000", "/soc@03000000/sdmmc@04020000";
		mmc2 = "/soc@03000000/sdmmc@04022000", "/soc@03000000/sdmmc@04022000";
		nand0 = "/soc@03000000/nand0@04011000", "/soc@03000000/nand0@04011000";
		spinand = "/soc@03000000/spinand@05010000", "/soc@03000000/spinand@05010000";
		disp = "/soc@03000000/disp@01000000", "/soc@03000000/disp@01000000";
		lcd0 = "/soc@03000000/lcd0@01c0c000", "/soc@03000000/lcd0@01c0c000";
		hdmi = "/soc@03000000/hdmi@06000000", "/soc@03000000/hdmi@06000000";
		pwm = "/soc@03000000/pwm@0300a000", "/soc@03000000/pwm@0300a000";
		pwm0 = "/soc@03000000/pwm0@0300a000", "/soc@03000000/pwm0@0300a000";
		pwm1 = "/soc@03000000/pwm1@0300a000", "/soc@03000000/pwm1@0300a000";
		pwm2 = "/soc@03000000/pwm2@0300a000", "/soc@03000000/pwm2@0300a000";
		pwm3 = "/soc@03000000/pwm3@0300a000", "/soc@03000000/pwm3@0300a000";
		pwm4 = "/soc@03000000/pwm4@0300a000", "/soc@03000000/pwm4@0300a000";
		pwm5 = "/soc@03000000/pwm5@0300a000", "/soc@03000000/pwm5@0300a000";
		pwm6 = "/soc@03000000/pwm6@0300a000", "/soc@03000000/pwm6@0300a000";
		pwm7 = "/soc@03000000/pwm7@0300a000", "/soc@03000000/pwm7@0300a000";
		pwm8 = "/soc@03000000/pwm8@0300a000", "/soc@03000000/pwm8@0300a000";
		tv0 = "/soc@03000000/tv0@06524000", "/soc@03000000/tv0@06524000";
		s_pwm = "/soc@03000000/s_pwm@0x07020c00", "/soc@03000000/s_pwm@0x07020c00";
		spwm0 = "/soc@03000000/spwm0@0x07020c00", "/soc@03000000/spwm0@0x07020c00";
		boot_disp = "/soc@03000000/boot_disp", "/soc@03000000/boot_disp";
		charger0 = "/soc@03000000/pmu@0/charger@0", "/soc@03000000/pmu@0/charger@0";
		regulator0 = "/soc@03000000/pmu@0/regulator@0", "/soc@03000000/pmu@0/regulator@0";
	};

	chosen {
		bootargs = "earlyprintk=sunxi-uart,0x01c28000 loglevel=8 initcall_debug=1 console=ttyS0 init=/init";
		linux,initrd-start = <0x0 0x0>;
		linux,initrd-end = <0x0 0x0>;
	};

	cpus {
		enable-method = "allwinner,sun8iw12p1";
		#address-cells = <0x1>;
		#size-cells = <0x0>;

		cpu@0 {
			device_type = "cpu";
			compatible = "arm,cortex-a7";
			reg = <0x0>;
			regulators = "vdd-cpua";
			clocks = <0xc4>;
			clock-frequency = <0x3c14dc00>;
			clock-latency = <0x1e8480>;
			operating-points-v2 = <0xc5>;
		};

		cpu@1 {
			device_type = "cpu";
			compatible = "arm,cortex-a7";
			reg = <0x1>;
			regulators = "vdd-cpua";
			clocks = <0xc4>;
			clock-frequency = <0x3c14dc00>;
			operating-points-v2 = <0xc5>;
		};

		cpu@2 {
			device_type = "cpu";
			compatible = "arm,cortex-a7";
			reg = <0x2>;
			regulators = "vdd-cpua";
			clock-names = "pll_cpu";
			clock-frequency = <0x3c14dc00>;
			operating-points-v2 = <0xc5>;
		};

		cpu@3 {
			device_type = "cpu";
			compatible = "arm,cortex-a7";
			reg = <0x3>;
			regulators = "vdd-cpua";
			clock-names = "pll_cpu";
			clock-frequency = <0x3c14dc00>;
			operating-points-v2 = <0xc5>;
		};
	};

	opp_dvfs_table {
		cluster_num = <0x1>;
		opp_table_count = <0x1>;

		opp_l_table0 {
			compatible = "allwinner,opp_l_table0";
			opp_count = <0x5>;
			opp-shared;
			linux,phandle = <0xc5>;
			phandle = <0xc5>;

			opp00 {
				opp-hz = <0x0 0x269fb200>;
				opp-microvolt = <0xc3500>;
				axi-bus-divide-ratio = <0x3>;
				clock-latency-ns = <0x1e8480>;
			};

			opp01 {
				opp-hz = <0x0 0x3c14dc00>;
				opp-microvolt = <0xcd140>;
				axi-bus-divide-ratio = <0x3>;
				clock-latency-ns = <0x1e8480>;
			};

			opp02 {
				opp-hz = <0x0 0x47868c00>;
				opp-microvolt = <0xdbba0>;
				axi-bus-divide-ratio = <0x3>;
				clock-latency-ns = <0x1e8480>;
			};

			opp03 {
				opp-hz = <0x0 0x54667200>;
				opp-microvolt = <0xea600>;
				axi-bus-divide-ratio = <0x3>;
				clock-latency-ns = <0x1e8480>;
			};

			opp04 {
				opp-hz = <0x0 0x5a1f4a00>;
				opp-microvolt = <0xf4240>;
				axi-bus-divide-ratio = <0x3>;
				clock-latency-ns = <0x1e8480>;
			};
		};
	};

	n_brom {
		compatible = "allwinner,n-brom";
		reg = <0x0 0x0 0x0 0xc000>;
	};

	s_brom {
		compatible = "allwinner,s-brom";
		reg = <0x0 0x0 0x0 0x10000>;
	};

	sram_ctrl {
		device_type = "sram_ctrl";
		compatible = "allwinner,sram_ctrl";
		reg = <0x0 0x3000000 0x0 0x100>;
	};

	sram_a1 {
		compatible = "allwinner,sram_a1";
		reg = <0x0 0x10000 0x0 0x10000>;
	};

	sram_a2 {
		compatible = "allwinner,sram_a2";
		reg = <0x0 0x40000 0x0 0x14000>;
	};

	prcm {
		compatible = "allwinner,prcm";
		reg = <0x0 0x1f01400 0x0 0x400>;
	};

	cpuscfg {
		compatible = "allwinner,cpuscfg";
		reg = <0x0 0x1f01c00 0x0 0x400>;
	};

	ion {
		compatible = "allwinner,sunxi-ion";

		system {
			type = <0x0>;
		};

		system_contig {
			type = <0x1>;
		};

		cma {
			type = <0x4>;
		};
	};

	dram {
		compatible = "allwinner,dram";
		clocks = <0xc6 0xc7>;
		clock-names = "pll_ddr0", "pll_ddr1";
		dram_clk = <0x0>;
		dram_type = <0x7>;
		dram_zq = <0x3b3bfb>;
		dram_odt_en = <0x1>;
		dram_para1 = <0x10f4>;
		dram_para2 = <0x0>;
		dram_mr0 = <0x1c70>;
		dram_mr1 = <0x40>;
		dram_mr2 = <0x18>;
		dram_mr3 = <0x2>;
		dram_tpr0 = <0x47194f>;
		dram_tpr1 = <0x1b1a94b>;
		dram_tpr2 = <0x61043>;
		dram_tpr3 = <0xb4787896>;
		dram_tpr4 = <0x0>;
		dram_tpr5 = <0x0>;
		dram_tpr6 = <0x0>;
		dram_tpr7 = <0xf22161c>;
		dram_tpr8 = <0x0>;
		dram_tpr9 = <0x0>;
		dram_tpr10 = <0x0>;
		dram_tpr11 = <0x0>;
		dram_tpr12 = <0x0>;
		dram_tpr13 = <0x4000284>;
		device_type = "dram";
	};

	memory@40000000 {
		device_type = "memory";
		reg = <0x0 0x40000000 0x0 0x20000000>;
	};

	interrupt-controller@03020000 {
		compatible = "arm,cortex-a15-gic", "arm,cortex-a9-gic";
		#interrupt-cells = <0x3>;
		#address-cells = <0x0>;
		device_type = "gic";
		interrupt-controller;
		reg = <0x0 0x3021000 0x0 0x1000 0x0 0x3022000 0x0 0x2000 0x0 0x3024000 0x0 0x2000 0x0 0x3026000 0x0 0x2000>;
		interrupts = <0x1 0x9 0xf04>;
		linux,phandle = <0x1>;
		phandle = <0x1>;
	};

	sunxi-sid@03006000 {
		compatible = "allwinner,sunxi-sid";
		device_type = "sid";
		reg = <0x0 0x3006000 0x0 0x200>;
	};

	sunxi-chipid@03006200 {
		compatible = "allwinner,sunxi-chipid";
		device_type = "chipid";
		reg = <0x0 0x3006200 0x0 0xc0>;
	};

	timer {
		compatible = "arm,armv7-timer";
		interrupts = <0x1 0xd 0xff01 0x1 0xe 0xff01 0x1 0xb 0xff01 0x1 0xa 0xff01>;
		clock-frequency = <0x16e3600>;
		arm,cpu-registers-not-fw-configured;
	};

	pmu {
		compatible = "arm,armv8-pmuv3";
		interrupts = <0x0 0x8a 0x4 0x0 0x8b 0x4 0x0 0x8c 0x4 0x0 0x8d 0x4>;
	};

	dramfreq {
		compatible = "allwinner,sunxi-dramfreq";
		reg = <0x0 0x1c62000 0x0 0x1000 0x0 0x1c63000 0x0 0x1000 0x0 0x1c20000 0x0 0x800>;
		interrupts = <0x0 0x45 0x4>;
		status = "okay";
	};

	uboot {
	};

	wlan {
		compatible = "allwinner,sunxi-wlan";
		clocks = <0xc8>;
		wlan_busnum = <0x1>;
		wlan_usbnum = <0x3>;
		wlan_power = "vcc33-wifi";
		wlan_io_regulator = "vcc18-wifi";
		wlan_en;
		status = "disabled";
		device_type = "wlan";
		wlan_regon = <0xc9 0xb 0x4 0x1 0xffffffff 0xffffffff 0x0>;
		wlan_hostwake = <0xc9 0xb 0x5 0x6 0xffffffff 0xffffffff 0x0>;
	};

	bt {
		compatible = "allwinner,sunxi-bt";
		clocks = <0xc8>;
		bt_power = "vcc18-wifi";
		bt_io_regulator = "vcc-pg";
		status = "disabled";
		device_type = "bt";
		bt_rst_n = <0xc9 0xb 0xc 0x1 0xffffffff 0xffffffff 0x0>;
	};

	btlpm {
		compatible = "allwinner,sunxi-btlpm";
		uart_index = <0x1>;
		status = "disabled";
		device_type = "btlpm";
		bt_wake = <0xc9 0xb 0xb 0x1 0xffffffff 0xffffffff 0x1>;
		bt_hostwake = <0xc9 0xb 0x6 0x6 0xffffffff 0xffffffff 0x0>;
	};
};
